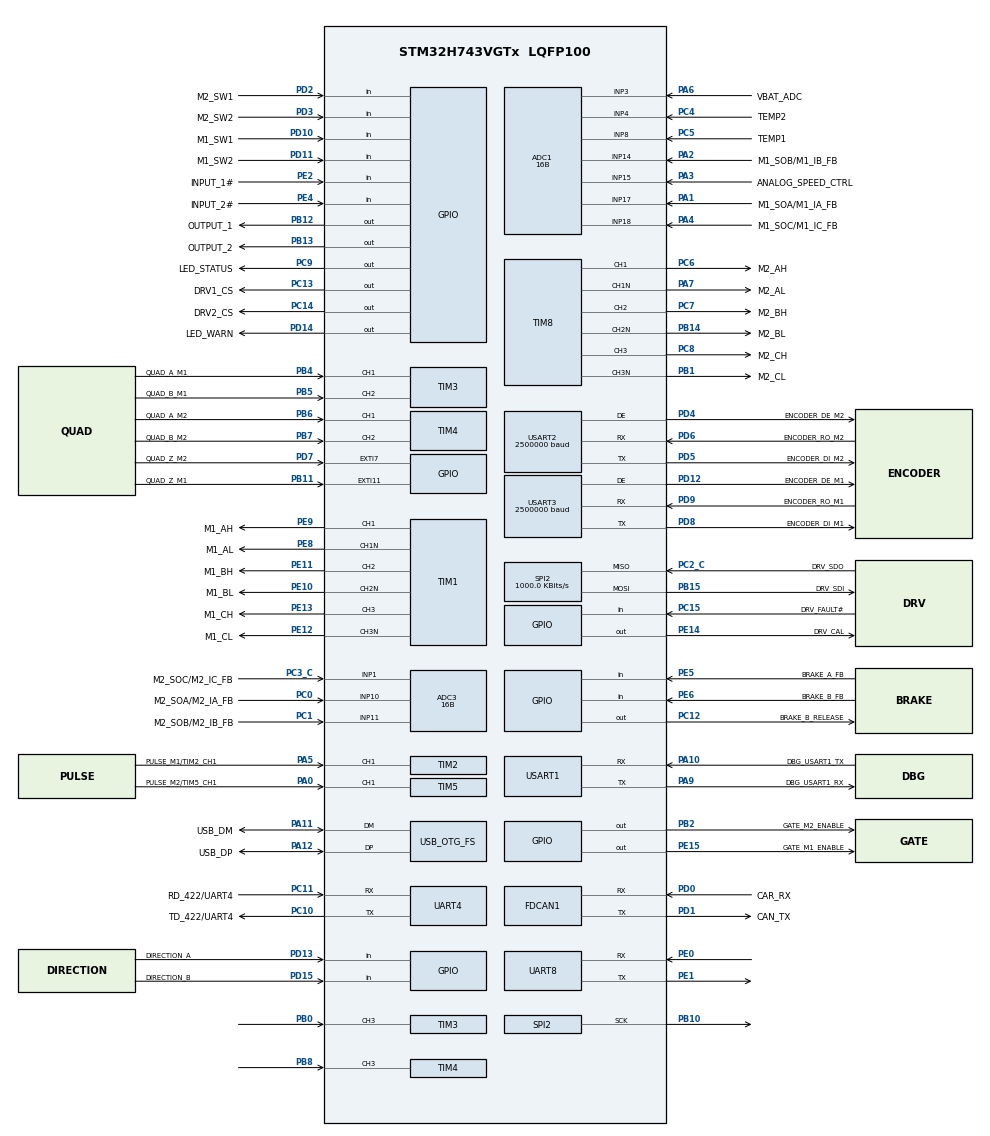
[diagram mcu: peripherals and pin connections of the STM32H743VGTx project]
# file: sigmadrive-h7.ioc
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ADC1.Channel-1\#ChannelRegularConversion=ADC_CHANNEL_17
ADC1.Channel-2\#ChannelRegularConversion=ADC_CHANNEL_14
ADC1.Channel-3\#ChannelRegularConversion=ADC_CHANNEL_18
ADC1.Channel-4\#ChannelRegularConversion=ADC_CHANNEL_3
ADC1.Channel-5\#ChannelRegularConversion=ADC_CHANNEL_4
ADC1.Channel-6\#ChannelRegularConversion=ADC_CHANNEL_8
ADC1.Channel-7\#ChannelRegularConversion=ADC_CHANNEL_15
ADC1.ClockPrescaler=ADC_CLOCK_ASYNC_DIV2
ADC1.ClockPrescalerADC3=ADC_CLOCK_ASYNC_DIV2
ADC1.ConversionDataManagement=ADC_CONVERSIONDATA_DMA_CIRCULAR
ADC1.EOCSelection=ADC_EOC_SEQ_CONV
ADC1.EnableInjectedConversion=ENABLE
ADC1.ExternalTrigConv=ADC_EXTERNALTRIG_T1_TRGO2
ADC1.ExternalTrigConvEdge=ADC_EXTERNALTRIGCONVEDGE_RISINGFALLING
ADC1.ExternalTrigInjecConv=ADC_EXTERNALTRIGINJEC_T1_TRGO2
ADC1.ExternalTrigInjecConvEdge=ADC_EXTERNALTRIGINJECCONV_EDGE_RISINGFALLING
ADC1.InjNumberOfConversion=3
ADC1.InjectedChannel-10\#ChannelInjectedConversion=ADC_CHANNEL_18
ADC1.InjectedChannel-8\#ChannelInjectedConversion=ADC_CHANNEL_17
ADC1.InjectedChannel-9\#ChannelInjectedConversion=ADC_CHANNEL_14
ADC1.InjectedOffsetNumber-10\#ChannelInjectedConversion=ADC_OFFSET_NONE
ADC1.InjectedOffsetNumber-8\#ChannelInjectedConversion=ADC_OFFSET_NONE
ADC1.InjectedOffsetNumber-9\#ChannelInjectedConversion=ADC_OFFSET_NONE
ADC1.InjectedOffsetSaturation-10\#ChannelInjectedConversion=DISABLE
ADC1.InjectedOffsetSaturation-8\#ChannelInjectedConversion=DISABLE
ADC1.InjectedOffsetSaturation-9\#ChannelInjectedConversion=DISABLE
ADC1.InjectedRank-10\#ChannelInjectedConversion=3
ADC1.InjectedRank-8\#ChannelInjectedConversion=1
ADC1.InjectedRank-9\#ChannelInjectedConversion=2
ADC1.InjectedSamplingTime-10\#ChannelInjectedConversion=ADC_SAMPLETIME_1CYCLE_5
ADC1.InjectedSamplingTime-8\#ChannelInjectedConversion=ADC_SAMPLETIME_1CYCLE_5
ADC1.InjectedSamplingTime-9\#ChannelInjectedConversion=ADC_SAMPLETIME_1CYCLE_5
ADC1.NbrOfConversion=7
ADC1.NbrOfConversionFlag=1
ADC1.OffsetNumber-2\#ChannelRegularConversion=ADC_OFFSET_NONE
ADC1.OffsetNumber-3\#ChannelRegularConversion=ADC_OFFSET_NONE
ADC1.OffsetNumber-4\#ChannelRegularConversion=ADC_OFFSET_NONE
ADC1.OffsetNumber-5\#ChannelRegularConversion=ADC_OFFSET_NONE
ADC1.OffsetNumber-6\#ChannelRegularConversion=ADC_OFFSET_NONE
ADC1.OffsetNumber-7\#ChannelRegularConversion=ADC_OFFSET_NONE
ADC1.Rank-2\#ChannelRegularConversion=2
ADC1.Rank-3\#ChannelRegularConversion=3
ADC1.Rank-4\#ChannelRegularConversion=4
ADC1.Rank-5\#ChannelRegularConversion=5
ADC1.Rank-6\#ChannelRegularConversion=6
ADC1.Rank-7\#ChannelRegularConversion=7
ADC1.Resolution=ADC_RESOLUTION_16B
ADC1.SamplingTime-1\#ChannelRegularConversion=ADC_SAMPLETIME_1CYCLE_5
ADC1.SamplingTime-2\#ChannelRegularConversion=ADC_SAMPLETIME_1CYCLE_5
ADC1.SamplingTime-3\#ChannelRegularConversion=ADC_SAMPLETIME_1CYCLE_5
ADC1.SamplingTime-4\#ChannelRegularConversion=ADC_SAMPLETIME_1CYCLE_5
ADC1.SamplingTime-5\#ChannelRegularConversion=ADC_SAMPLETIME_1CYCLE_5
ADC1.SamplingTime-6\#ChannelRegularConversion=ADC_SAMPLETIME_1CYCLE_5
ADC1.SamplingTime-7\#ChannelRegularConversion=ADC_SAMPLETIME_1CYCLE_5
ADC1.master=1
ADC3.Channel-0\#ChannelRegularConversion=ADC_CHANNEL_10
ADC3.Channel-1\#ChannelRegularConversion=ADC_CHANNEL_11
ADC3.Channel-2\#ChannelRegularConversion=ADC_CHANNEL_1
ADC3.ClockPrescaler=ADC_CLOCK_ASYNC_DIV2
ADC3.ClockPrescalerADC3=ADC_CLOCK_ASYNC_DIV2
ADC3.ConversionDataManagement=ADC_CONVERSIONDATA_DMA_CIRCULAR
ADC3.EnableInjectedConversion=ENABLE
ADC3.ExternalTrigConv=ADC_EXTERNALTRIG_T8_TRGO2
ADC3.ExternalTrigInjecConv=ADC_EXTERNALTRIGINJEC_T8_TRGO2
ADC3.ExternalTrigInjecConvEdge=ADC_EXTERNALTRIGINJECCONV_EDGE_RISINGFALLING
ADC3.InjNumberOfConversion=3
ADC3.InjectedChannel-3\#ChannelInjectedConversion=ADC_CHANNEL_10
ADC3.InjectedChannel-4\#ChannelInjectedConversion=ADC_CHANNEL_11
ADC3.InjectedChannel-5\#ChannelInjectedConversion=ADC_CHANNEL_1
ADC3.InjectedOffsetNumber-3\#ChannelInjectedConversion=ADC_OFFSET_NONE
ADC3.InjectedOffsetNumber-4\#ChannelInjectedConversion=ADC_OFFSET_NONE
ADC3.InjectedOffsetNumber-5\#ChannelInjectedConversion=ADC_OFFSET_NONE
ADC3.InjectedOffsetSaturation-3\#ChannelInjectedConversion=DISABLE
ADC3.InjectedOffsetSaturation-4\#ChannelInjectedConversion=DISABLE
ADC3.InjectedOffsetSaturation-5\#ChannelInjectedConversion=DISABLE
ADC3.InjectedOffsetSignedSaturation-3\#ChannelInjectedConversion=DISABLE
ADC3.InjectedOffsetSignedSaturation-4\#ChannelInjectedConversion=DISABLE
ADC3.InjectedOffsetSignedSaturation-5\#ChannelInjectedConversion=DISABLE
ADC3.InjectedRank-3\#ChannelInjectedConversion=1
ADC3.InjectedRank-4\#ChannelInjectedConversion=2
ADC3.InjectedRank-5\#ChannelInjectedConversion=3
ADC3.InjectedSamplingTime-3\#ChannelInjectedConversion=ADC_SAMPLETIME_1CYCLE_5
ADC3.InjectedSamplingTime-4\#ChannelInjectedConversion=ADC_SAMPLETIME_1CYCLE_5
ADC3.InjectedSamplingTime-5\#ChannelInjectedConversion=ADC_SAMPLETIME_1CYCLE_5
ADC3.NbrOfConversion=3
ADC3.NbrOfConversionFlag=1
ADC3.OffsetNumber-0\#ChannelRegularConversion=ADC_OFFSET_NONE
ADC3.OffsetNumber-1\#ChannelRegularConversion=ADC_OFFSET_NONE
ADC3.OffsetNumber-2\#ChannelRegularConversion=ADC_OFFSET_NONE
ADC3.OffsetSignedSaturation-0\#ChannelRegularConversion=DISABLE
ADC3.OffsetSignedSaturation-1\#ChannelRegularConversion=DISABLE
ADC3.OffsetSignedSaturation-2\#ChannelRegularConversion=DISABLE
ADC3.Rank-0\#ChannelRegularConversion=1
ADC3.Rank-1\#ChannelRegularConversion=2
ADC3.Rank-2\#ChannelRegularConversion=3
ADC3.Resolution=ADC_RESOLUTION_16B
ADC3.SamplingTime-0\#ChannelRegularConversion=ADC_SAMPLETIME_1CYCLE_5
ADC3.SamplingTime-1\#ChannelRegularConversion=ADC_SAMPLETIME_1CYCLE_5
ADC3.SamplingTime-2\#ChannelRegularConversion=ADC_SAMPLETIME_1CYCLE_5
ADC3.injectedQueueMode=DISABLE
CORTEX_M7.CPU_DCache=Disabled
CORTEX_M7.CPU_ICache=Disabled
CORTEX_M7.MPU_Control=__NULL
CORTEX_M7.default_mode_Activation=0
Dma.ADC1.8.Direction=DMA_PERIPH_TO_MEMORY
Dma.ADC1.8.EventEnable=DISABLE
Dma.ADC1.8.FIFOMode=DMA_FIFOMODE_ENABLE
Dma.ADC1.8.FIFOThreshold=DMA_FIFO_THRESHOLD_FULL
Dma.ADC1.8.Instance=DMA2_Stream0
Dma.ADC1.8.MemBurst=DMA_MBURST_SINGLE
Dma.ADC1.8.MemDataAlignment=DMA_MDATAALIGN_WORD
Dma.ADC1.8.MemInc=DMA_MINC_ENABLE
Dma.ADC1.8.Mode=DMA_CIRCULAR
Dma.ADC1.8.PeriphBurst=DMA_PBURST_SINGLE
Dma.ADC1.8.PeriphDataAlignment=DMA_PDATAALIGN_WORD
Dma.ADC1.8.PeriphInc=DMA_PINC_DISABLE
Dma.ADC1.8.Polarity=HAL_DMAMUX_REQ_GEN_RISING
Dma.ADC1.8.Priority=DMA_PRIORITY_LOW
Dma.ADC1.8.RequestNumber=1
Dma.ADC1.8.SignalID=NONE
Dma.ADC1.8.SyncEnable=DISABLE
Dma.ADC1.8.SyncPolarity=HAL_DMAMUX_SYNC_NO_EVENT
Dma.ADC1.8.SyncRequestNumber=1
Dma.ADC1.8.SyncSignalID=NONE
Dma.ADC3.9.Direction=DMA_PERIPH_TO_MEMORY
Dma.ADC3.9.EventEnable=DISABLE
Dma.ADC3.9.FIFOMode=DMA_FIFOMODE_ENABLE
Dma.ADC3.9.FIFOThreshold=DMA_FIFO_THRESHOLD_FULL
Dma.ADC3.9.Instance=DMA2_Stream2
Dma.ADC3.9.MemBurst=DMA_MBURST_SINGLE
Dma.ADC3.9.MemDataAlignment=DMA_MDATAALIGN_WORD
Dma.ADC3.9.MemInc=DMA_MINC_ENABLE
Dma.ADC3.9.Mode=DMA_CIRCULAR
Dma.ADC3.9.PeriphBurst=DMA_PBURST_SINGLE
Dma.ADC3.9.PeriphDataAlignment=DMA_PDATAALIGN_WORD
Dma.ADC3.9.PeriphInc=DMA_PINC_DISABLE
Dma.ADC3.9.Polarity=HAL_DMAMUX_REQ_GEN_RISING
Dma.ADC3.9.Priority=DMA_PRIORITY_LOW
Dma.ADC3.9.RequestNumber=1
Dma.ADC3.9.SignalID=NONE
Dma.ADC3.9.SyncEnable=DISABLE
Dma.ADC3.9.SyncPolarity=HAL_DMAMUX_SYNC_NO_EVENT
Dma.ADC3.9.SyncRequestNumber=1
Dma.ADC3.9.SyncSignalID=NONE
Dma.Request0=UART8_TX
Dma.Request1=UART8_RX
Dma.Request2=USART1_TX
Dma.Request3=USART1_RX
Dma.Request4=USART2_RX
Dma.Request5=USART3_RX
Dma.Request6=UART4_TX
Dma.Request7=UART4_RX
Dma.Request8=ADC1
Dma.Request9=ADC3
Dma.UART4_RX.7.Direction=DMA_PERIPH_TO_MEMORY
Dma.UART4_RX.7.EventEnable=DISABLE
Dma.UART4_RX.7.FIFOMode=DMA_FIFOMODE_DISABLE
Dma.UART4_RX.7.Instance=DMA1_Stream2
Dma.UART4_RX.7.MemDataAlignment=DMA_MDATAALIGN_BYTE
Dma.UART4_RX.7.MemInc=DMA_MINC_ENABLE
Dma.UART4_RX.7.Mode=DMA_CIRCULAR
Dma.UART4_RX.7.PeriphDataAlignment=DMA_PDATAALIGN_BYTE
Dma.UART4_RX.7.PeriphInc=DMA_PINC_DISABLE
Dma.UART4_RX.7.Polarity=HAL_DMAMUX_REQ_GEN_RISING
Dma.UART4_RX.7.Priority=DMA_PRIORITY_LOW
Dma.UART4_RX.7.RequestNumber=1
Dma.UART4_RX.7.SignalID=NONE
Dma.UART4_RX.7.SyncEnable=DISABLE
Dma.UART4_RX.7.SyncPolarity=HAL_DMAMUX_SYNC_NO_EVENT
Dma.UART4_RX.7.SyncRequestNumber=1
Dma.UART4_RX.7.SyncSignalID=NONE
Dma.UART4_TX.6.Direction=DMA_MEMORY_TO_PERIPH
Dma.UART4_TX.6.EventEnable=DISABLE
Dma.UART4_TX.6.FIFOMode=DMA_FIFOMODE_DISABLE
Dma.UART4_TX.6.Instance=DMA1_Stream4
Dma.UART4_TX.6.MemDataAlignment=DMA_MDATAALIGN_BYTE
Dma.UART4_TX.6.MemInc=DMA_MINC_ENABLE
Dma.UART4_TX.6.Mode=DMA_NORMAL
Dma.UART4_TX.6.PeriphDataAlignment=DMA_PDATAALIGN_BYTE
Dma.UART4_TX.6.PeriphInc=DMA_PINC_DISABLE
Dma.UART4_TX.6.Polarity=HAL_DMAMUX_REQ_GEN_RISING
Dma.UART4_TX.6.Priority=DMA_PRIORITY_LOW
Dma.UART4_TX.6.RequestNumber=1
Dma.UART4_TX.6.SignalID=NONE
Dma.UART4_TX.6.SyncEnable=DISABLE
Dma.UART4_TX.6.SyncPolarity=HAL_DMAMUX_SYNC_NO_EVENT
Dma.UART4_TX.6.SyncRequestNumber=1
Dma.UART4_TX.6.SyncSignalID=NONE
Dma.UART8_RX.1.Direction=DMA_PERIPH_TO_MEMORY
Dma.UART8_RX.1.EventEnable=DISABLE
Dma.UART8_RX.1.FIFOMode=DMA_FIFOMODE_DISABLE
Dma.UART8_RX.1.Instance=DMA1_Stream6
Dma.UART8_RX.1.MemDataAlignment=DMA_MDATAALIGN_BYTE
Dma.UART8_RX.1.MemInc=DMA_MINC_ENABLE
Dma.UART8_RX.1.Mode=DMA_CIRCULAR
Dma.UART8_RX.1.PeriphDataAlignment=DMA_PDATAALIGN_BYTE
Dma.UART8_RX.1.PeriphInc=DMA_PINC_DISABLE
Dma.UART8_RX.1.Polarity=HAL_DMAMUX_REQ_GEN_RISING
Dma.UART8_RX.1.Priority=DMA_PRIORITY_LOW
Dma.UART8_RX.1.RequestNumber=1
Dma.UART8_RX.1.SignalID=NONE
Dma.UART8_RX.1.SyncEnable=DISABLE
Dma.UART8_RX.1.SyncPolarity=HAL_DMAMUX_SYNC_NO_EVENT
Dma.UART8_RX.1.SyncRequestNumber=1
Dma.UART8_RX.1.SyncSignalID=NONE
Dma.UART8_TX.0.Direction=DMA_MEMORY_TO_PERIPH
Dma.UART8_TX.0.EventEnable=DISABLE
Dma.UART8_TX.0.FIFOMode=DMA_FIFOMODE_DISABLE
Dma.UART8_TX.0.Instance=DMA1_Stream0
Dma.UART8_TX.0.MemDataAlignment=DMA_MDATAALIGN_BYTE
Dma.UART8_TX.0.MemInc=DMA_MINC_ENABLE
Dma.UART8_TX.0.Mode=DMA_NORMAL
Dma.UART8_TX.0.PeriphDataAlignment=DMA_PDATAALIGN_BYTE
Dma.UART8_TX.0.PeriphInc=DMA_PINC_DISABLE
Dma.UART8_TX.0.Polarity=HAL_DMAMUX_REQ_GEN_RISING
Dma.UART8_TX.0.Priority=DMA_PRIORITY_LOW
Dma.UART8_TX.0.RequestNumber=1
Dma.UART8_TX.0.SignalID=NONE
Dma.UART8_TX.0.SyncEnable=DISABLE
Dma.UART8_TX.0.SyncPolarity=HAL_DMAMUX_SYNC_NO_EVENT
Dma.UART8_TX.0.SyncRequestNumber=1
Dma.UART8_TX.0.SyncSignalID=NONE
Dma.USART1_RX.3.Direction=DMA_PERIPH_TO_MEMORY
Dma.USART1_RX.3.EventEnable=DISABLE
Dma.USART1_RX.3.FIFOMode=DMA_FIFOMODE_DISABLE
Dma.USART1_RX.3.Instance=DMA2_Stream5
Dma.USART1_RX.3.MemDataAlignment=DMA_MDATAALIGN_BYTE
Dma.USART1_RX.3.MemInc=DMA_MINC_ENABLE
Dma.USART1_RX.3.Mode=DMA_CIRCULAR
Dma.USART1_RX.3.PeriphDataAlignment=DMA_PDATAALIGN_BYTE
Dma.USART1_RX.3.PeriphInc=DMA_PINC_DISABLE
Dma.USART1_RX.3.Polarity=HAL_DMAMUX_REQ_GEN_RISING
Dma.USART1_RX.3.Priority=DMA_PRIORITY_LOW
Dma.USART1_RX.3.RequestNumber=1
Dma.USART1_RX.3.SignalID=NONE
Dma.USART1_RX.3.SyncEnable=DISABLE
Dma.USART1_RX.3.SyncPolarity=HAL_DMAMUX_SYNC_NO_EVENT
Dma.USART1_RX.3.SyncRequestNumber=1
Dma.USART1_RX.3.SyncSignalID=NONE
Dma.USART1_TX.2.Direction=DMA_MEMORY_TO_PERIPH
Dma.USART1_TX.2.EventEnable=DISABLE
Dma.USART1_TX.2.FIFOMode=DMA_FIFOMODE_DISABLE
Dma.USART1_TX.2.Instance=DMA2_Stream7
Dma.USART1_TX.2.MemDataAlignment=DMA_MDATAALIGN_BYTE
Dma.USART1_TX.2.MemInc=DMA_MINC_ENABLE
Dma.USART1_TX.2.Mode=DMA_NORMAL
Dma.USART1_TX.2.PeriphDataAlignment=DMA_PDATAALIGN_BYTE
Dma.USART1_TX.2.PeriphInc=DMA_PINC_DISABLE
Dma.USART1_TX.2.Polarity=HAL_DMAMUX_REQ_GEN_RISING
Dma.USART1_TX.2.Priority=DMA_PRIORITY_LOW
Dma.USART1_TX.2.RequestNumber=1
Dma.USART1_TX.2.SignalID=NONE
Dma.USART1_TX.2.SyncEnable=DISABLE
Dma.USART1_TX.2.SyncPolarity=HAL_DMAMUX_SYNC_NO_EVENT
Dma.USART1_TX.2.SyncRequestNumber=1
Dma.USART1_TX.2.SyncSignalID=NONE
Dma.USART2_RX.4.Direction=DMA_PERIPH_TO_MEMORY
Dma.USART2_RX.4.EventEnable=DISABLE
Dma.USART2_RX.4.FIFOMode=DMA_FIFOMODE_DISABLE
Dma.USART2_RX.4.Instance=DMA1_Stream5
Dma.USART2_RX.4.MemDataAlignment=DMA_MDATAALIGN_BYTE
Dma.USART2_RX.4.MemInc=DMA_MINC_ENABLE
Dma.USART2_RX.4.Mode=DMA_NORMAL
Dma.USART2_RX.4.PeriphDataAlignment=DMA_PDATAALIGN_BYTE
Dma.USART2_RX.4.PeriphInc=DMA_PINC_DISABLE
Dma.USART2_RX.4.Polarity=HAL_DMAMUX_REQ_GEN_RISING
Dma.USART2_RX.4.Priority=DMA_PRIORITY_VERY_HIGH
Dma.USART2_RX.4.RequestNumber=1
Dma.USART2_RX.4.SignalID=NONE
Dma.USART2_RX.4.SyncEnable=DISABLE
Dma.USART2_RX.4.SyncPolarity=HAL_DMAMUX_SYNC_NO_EVENT
Dma.USART2_RX.4.SyncRequestNumber=1
Dma.USART2_RX.4.SyncSignalID=NONE
Dma.USART3_RX.5.Direction=DMA_PERIPH_TO_MEMORY
Dma.USART3_RX.5.EventEnable=DISABLE
Dma.USART3_RX.5.FIFOMode=DMA_FIFOMODE_DISABLE
Dma.USART3_RX.5.Instance=DMA1_Stream1
Dma.USART3_RX.5.MemDataAlignment=DMA_MDATAALIGN_BYTE
Dma.USART3_RX.5.MemInc=DMA_MINC_ENABLE
Dma.USART3_RX.5.Mode=DMA_NORMAL
Dma.USART3_RX.5.PeriphDataAlignment=DMA_PDATAALIGN_BYTE
Dma.USART3_RX.5.PeriphInc=DMA_PINC_DISABLE
Dma.USART3_RX.5.Polarity=HAL_DMAMUX_REQ_GEN_RISING
Dma.USART3_RX.5.Priority=DMA_PRIORITY_VERY_HIGH
Dma.USART3_RX.5.RequestNumber=1
Dma.USART3_RX.5.SignalID=NONE
Dma.USART3_RX.5.SyncEnable=DISABLE
Dma.USART3_RX.5.SyncPolarity=HAL_DMAMUX_SYNC_NO_EVENT
Dma.USART3_RX.5.SyncRequestNumber=1
Dma.USART3_RX.5.SyncSignalID=NONE
FDCAN1.CalculateBaudRateNominal=150000
FDCAN1.CalculateTimeBitNominal=6666
FDCAN1.CalculateTimeQuantumNominal=1333.3333333333333
FREERTOS.HEAP_NUMBER=3
FREERTOS.Tasks01=defaultTask,24,2048,StartDefaultTask,Default,NULL,Dynamic,NULL,NULL
FREERTOS.configTOTAL_HEAP_SIZE=353600
Mcu.Family=STM32H7
Mcu.Name=STM32H743VGTx
Mcu.Package=LQFP100
Mcu.UserConstants=TIM1_PERIOD_CLOCKS,6000;TIM1_RCR,0;TIMER_CORE_CLOCK,240000000
NVIC.ADC3_IRQn=true\:5\:0\:false\:false\:true\:true\:true\:true\:true
NVIC.ADC_IRQn=true\:5\:0\:false\:false\:true\:true\:true\:true\:true
NVIC.DMA1_Stream0_IRQn=true\:5\:0\:false\:false\:true\:true\:false\:true\:true
NVIC.DMA1_Stream1_IRQn=true\:5\:0\:false\:false\:true\:true\:false\:true\:true
NVIC.DMA1_Stream2_IRQn=true\:5\:0\:false\:false\:true\:true\:false\:true\:true
NVIC.DMA1_Stream4_IRQn=true\:5\:0\:false\:false\:true\:false\:false\:true\:true
NVIC.DMA1_Stream5_IRQn=true\:5\:0\:false\:false\:true\:false\:false\:true\:true
NVIC.DMA1_Stream6_IRQn=true\:5\:0\:false\:false\:true\:true\:false\:true\:true
NVIC.DMA2_Stream0_IRQn=true\:5\:0\:false\:false\:true\:true\:false\:true\:true
NVIC.DMA2_Stream2_IRQn=true\:5\:0\:false\:false\:true\:false\:false\:true\:true
NVIC.DMA2_Stream5_IRQn=true\:5\:0\:false\:false\:true\:false\:false\:true\:true
NVIC.DMA2_Stream7_IRQn=true\:5\:0\:false\:false\:true\:false\:false\:true\:true
NVIC.OTG_FS_IRQn=true\:5\:0\:false\:false\:true\:true\:false\:true\:true
NVIC.PriorityGroup=NVIC_PRIORITYGROUP_4
NVIC.TIM1_UP_IRQn=true\:5\:0\:false\:false\:true\:true\:true\:true\:true
NVIC.TIM7_IRQn=true\:15\:0\:false\:false\:true\:false\:false\:true\:true
NVIC.TimeBase=TIM7_IRQn
NVIC.TimeBaseIP=TIM7
NVIC.UART4_IRQn=true\:5\:0\:false\:false\:true\:true\:true\:true\:true
NVIC.UART8_IRQn=true\:5\:0\:false\:false\:true\:true\:true\:true\:true
NVIC.USART1_IRQn=true\:5\:0\:false\:false\:true\:true\:true\:true\:true
NVIC.USART2_IRQn=true\:5\:0\:false\:false\:true\:true\:true\:true\:true
NVIC.USART3_IRQn=true\:5\:0\:false\:false\:true\:true\:true\:true\:true
PA0.GPIO_Label=PULSE_M2/TIM5_CH1
PA0.Signal=S_TIM5_CH1
PA1.GPIO_Label=M1_SOA/M1_IA_FB
PA1.GPIO_Mode=GPIO_MODE_ANALOG
PA1.GPIO_PuPd=GPIO_NOPULL
PA1.Mode=IN17-Single-Ended
PA1.Signal=ADC1_INP17
PA10.GPIO_Label=DBG_USART1_TX
PA10.GPIO_Speed=GPIO_SPEED_FREQ_VERY_HIGH
PA10.Mode=Asynchronous
PA10.Signal=USART1_RX
PA11.GPIO_Label=USB_DM
PA11.Mode=Device_Only
PA11.Signal=USB_OTG_FS_DM
PA12.GPIO_Label=USB_DP
PA12.Mode=Device_Only
PA12.Signal=USB_OTG_FS_DP
PA13\ (JTMS/SWDIO).Signal=DEBUG_JTMS-SWDIO
PA14\ (JTCK/SWCLK).Signal=DEBUG_JTCK-SWCLK
PA2.GPIO_Label=M1_SOB/M1_IB_FB
PA2.GPIO_Mode=GPIO_MODE_ANALOG
PA2.GPIO_PuPd=GPIO_NOPULL
PA2.Signal=ADCx_INP14
PA3.GPIO_Label=ANALOG_SPEED_CTRL
PA3.GPIO_Mode=GPIO_MODE_ANALOG
PA3.GPIO_PuPd=GPIO_NOPULL
PA3.Signal=ADCx_INP15
PA4.GPIO_Label=M1_SOC/M1_IC_FB
PA4.GPIO_Mode=GPIO_MODE_ANALOG
PA4.GPIO_PuPd=GPIO_NOPULL
PA4.Signal=ADCx_INP18
PA5.GPIO_Label=PULSE_M1/TIM2_CH1
PA5.Signal=S_TIM2_CH1_ETR
PA6.GPIO_Label=VBAT_ADC
PA6.GPIO_Mode=GPIO_MODE_ANALOG
PA6.GPIO_PuPd=GPIO_NOPULL
PA6.Signal=ADCx_INP3
PA7.GPIO_Label=M2_AL
PA7.Mode=PWM Generation1 CH1 CH1N
PA7.Signal=TIM8_CH1N
PA9.GPIO_Label=DBG_USART1_RX
PA9.GPIO_Speed=GPIO_SPEED_FREQ_VERY_HIGH
PA9.Mode=Asynchronous
PA9.Signal=USART1_TX
PB0.Signal=S_TIM3_CH3
PB1.GPIO_Label=M2_CL
PB1.Mode=PWM Generation3 CH3 CH3N
PB1.Signal=TIM8_CH3N
PB10.Mode=Full_Duplex_Master
PB10.Signal=SPI2_SCK
PB11.GPIO_Label=QUAD_Z_M1
PB11.Signal=GPXTI11
PB12.GPIO_Label=OUTPUT_1
PB12.Signal=GPIO_Output
PB13.GPIO_Label=OUTPUT_2
PB13.Signal=GPIO_Output
PB14.GPIO_Label=M2_BL
PB14.Mode=PWM Generation2 CH2 CH2N
PB14.Signal=TIM8_CH2N
PB15.GPIO_Label=DRV_SDI
PB15.Mode=Full_Duplex_Master
PB15.Signal=SPI2_MOSI
PB2.GPIO_Label=GATE_M2_ENABLE
PB2.Signal=GPIO_Output
PB3\ (JTDO/TRACESWO).Signal=DEBUG_JTDO-SWO
PB4\ (NJTRST).GPIO_Label=QUAD_A_M1
PB4\ (NJTRST).Signal=S_TIM3_CH1
PB5.GPIO_Label=QUAD_B_M1
PB5.Signal=S_TIM3_CH2
PB6.GPIO_Label=QUAD_A_M2
PB6.Signal=S_TIM4_CH1
PB7.GPIO_Label=QUAD_B_M2
PB7.Signal=S_TIM4_CH2
PB8.Signal=S_TIM4_CH3
PC0.GPIO_Label=M2_SOA/M2_IA_FB
PC0.Signal=ADCx_INP10
PC1.GPIO_Label=M2_SOB/M2_IB_FB
PC1.Signal=ADCx_INP11
PC10.GPIO_Label=TD_422/UART4
PC10.Mode=Asynchronous
PC10.Signal=UART4_TX
PC11.GPIO_Label=RD_422/UART4
PC11.Mode=Asynchronous
PC11.Signal=UART4_RX
PC12.GPIO_Label=BRAKE_B_RELEASE
PC12.Signal=GPIO_Output
PC13.GPIO_Label=DRV1_CS
PC13.Signal=GPIO_Output
PC14-OSC32_IN\ (OSC32_IN).GPIO_Label=DRV2_CS
PC14-OSC32_IN\ (OSC32_IN).Signal=GPIO_Output
PC15-OSC32_OUT\ (OSC32_OUT).GPIO_Label=DRV_FAULT\#
PC15-OSC32_OUT\ (OSC32_OUT).Signal=GPIO_Input
PC2_C.GPIO_Label=DRV_SDO
PC2_C.Mode=Full_Duplex_Master
PC2_C.Signal=SPI2_MISO
PC3_C.GPIO_Label=M2_SOC/M2_IC_FB
PC3_C.Mode=IN1-Single-Ended
PC3_C.Signal=ADC3_INP1
PC4.GPIO_Label=TEMP2
PC4.GPIO_Mode=GPIO_MODE_ANALOG
PC4.GPIO_PuPd=GPIO_NOPULL
PC4.Signal=ADCx_INP4
PC5.GPIO_Label=TEMP1
PC5.GPIO_Mode=GPIO_MODE_ANALOG
PC5.GPIO_PuPd=GPIO_NOPULL
PC5.Signal=ADCx_INP8
PC6.GPIO_Label=M2_AH
PC6.Signal=S_TIM8_CH1
PC7.GPIO_Label=M2_BH
PC7.Signal=S_TIM8_CH2
PC8.GPIO_Label=M2_CH
PC8.Signal=S_TIM8_CH3
PC9.GPIO_Label=LED_STATUS
PC9.Signal=GPIO_Output
PD0.GPIO_Label=CAR_RX
PD0.Mode=FDCAN_Activate
PD0.Signal=FDCAN1_RX
PD1.GPIO_Label=CAN_TX
PD1.Mode=FDCAN_Activate
PD1.Signal=FDCAN1_TX
PD10.GPIO_Label=M1_SW1
PD10.Signal=GPIO_Input
PD11.GPIO_Label=M1_SW2
PD11.Signal=GPIO_Input
PD12.GPIO_Label=ENCODER_DE_M1
PD12.Mode=Hardware Flow Control (RS485)
PD12.Signal=USART3_DE
PD13.GPIO_Label=DIRECTION_A
PD13.Signal=GPIO_Input
PD14.GPIO_Label=LED_WARN
PD14.Signal=GPIO_Output
PD15.GPIO_Label=DIRECTION_B
PD15.Signal=GPIO_Input
PD2.GPIO_Label=M2_SW1
PD2.Signal=GPIO_Input
PD3.GPIO_Label=M2_SW2
PD3.Signal=GPIO_Input
PD4.GPIO_Label=ENCODER_DE_M2
PD4.Mode=Hardware Flow Control (RS485)
PD4.Signal=USART2_DE
PD5.GPIO_Label=ENCODER_DI_M2
PD5.Mode=Asynchronous
PD5.Signal=USART2_TX
PD6.GPIO_Label=ENCODER_RO_M2
PD6.Mode=Asynchronous
PD6.Signal=USART2_RX
PD7.GPIO_Label=QUAD_Z_M2
PD7.Signal=GPXTI7
PD8.GPIO_Label=ENCODER_DI_M1
PD8.Mode=Asynchronous
PD8.Signal=USART3_TX
PD9.GPIO_Label=ENCODER_RO_M1
PD9.Mode=Asynchronous
PD9.Signal=USART3_RX
PE0.GPIO_Speed=GPIO_SPEED_FREQ_VERY_HIGH
PE0.Mode=Asynchronous
PE0.Signal=UART8_RX
PE1.GPIO_Speed=GPIO_SPEED_FREQ_VERY_HIGH
PE1.Mode=Asynchronous
PE1.Signal=UART8_TX
PE10.GPIO_Label=M1_BL
PE10.Mode=PWM Generation2 CH2 CH2N
PE10.Signal=TIM1_CH2N
PE11.GPIO_Label=M1_BH
PE11.Signal=S_TIM1_CH2
PE12.GPIO_Label=M1_CL
PE12.Mode=PWM Generation3 CH3 CH3N
PE12.Signal=TIM1_CH3N
PE13.GPIO_Label=M1_CH
PE13.Signal=S_TIM1_CH3
PE14.GPIO_Label=DRV_CAL
PE14.Signal=GPIO_Output
PE15.GPIO_Label=GATE_M1_ENABLE
PE15.Signal=GPIO_Output
PE2.GPIO_Label=INPUT_1\#
PE2.Signal=GPIO_Input
PE4.GPIO_Label=INPUT_2\#
PE4.Signal=GPIO_Input
PE5.GPIO_Label=BRAKE_A_FB
PE5.Signal=GPIO_Input
PE6.GPIO_Label=BRAKE_B_FB
PE6.Signal=GPIO_Input
PE8.GPIO_Label=M1_AL
PE8.Mode=PWM Generation1 CH1 CH1N
PE8.Signal=TIM1_CH1N
PE9.GPIO_Label=M1_AH
PE9.Signal=S_TIM1_CH1
PH0-OSC_IN\ (PH0).Mode=HSE-External-Oscillator
PH0-OSC_IN\ (PH0).Signal=RCC_OSC_IN
PH1-OSC_OUT\ (PH1).Mode=HSE-External-Oscillator
PH1-OSC_OUT\ (PH1).Signal=RCC_OSC_OUT
ProjectManager.HeapSize=0x200
ProjectManager.StackSize=0x400
ProjectManager.TargetToolchain=Makefile
RCC.ADCFreq_Value=37500000
RCC.APB1Freq_Value=120000000
RCC.APB2Freq_Value=120000000
RCC.APB3Freq_Value=120000000
RCC.APB4Freq_Value=120000000
RCC.CortexFreq_Value=480000000
RCC.D1PPRE=RCC_APB3_DIV2
RCC.D2PPRE1=RCC_APB1_DIV2
RCC.D2PPRE2=RCC_APB2_DIV2
RCC.D3PPRE=RCC_APB4_DIV2
RCC.DIVM1=3
RCC.DIVM2=1
RCC.DIVM3=1
RCC.DIVN1=240
RCC.DIVN2=12
RCC.DIVN3=16
RCC.DIVP2=4
RCC.DIVQ1=7
RCC.DIVQ2=3
RCC.DIVQ3=4
RCC.FDCANCLockSelection=RCC_FDCANCLKSOURCE_HSE
RCC.HCLKFreq_Value=240000000
RCC.HPRE=RCC_HCLK_DIV2
RCC.HSE_VALUE=12000000
RCC.PLL1_VCI_Range-AdvancedSettings=RCC_PLL1VCIRANGE_3
RCC.PLL1_VCO_SEL-AdvancedSettings=RCC_PLL1VCOMEDIUM
RCC.PLL2FRACN=4096
RCC.PLL3FRACN=0
RCC.PLLFRACN=0
RCC.PLLSourceVirtual=RCC_PLLSOURCE_HSE
RCC.ProductRev=revV
RCC.SPI123CLockSelection=RCC_SPI123CLKSOURCE_CLKP
RCC.SYSCLKFreq_VALUE=480000000
RCC.SYSCLKSource=RCC_SYSCLKSOURCE_PLLCLK
RCC.USART16CLockSelection=RCC_USART16CLKSOURCE_PLL2
RCC.USART234578CLockSelection=RCC_USART234578CLKSOURCE_PLL2
RCC.USBCLockSelection=RCC_USBCLKSOURCE_PLL3
RCC.USBFreq_Value=48000000
SH.ADCx_INP10.0=ADC3_INP10,IN10-Single-Ended
SH.ADCx_INP11.0=ADC3_INP11,IN11-Single-Ended
SH.ADCx_INP14.0=ADC1_INP14,IN14-Single-Ended
SH.ADCx_INP15.0=ADC1_INP15,IN15-Single-Ended
SH.ADCx_INP18.0=ADC1_INP18,IN18-Single-Ended
SH.ADCx_INP3.0=ADC1_INP3,IN3-Single-Ended
SH.ADCx_INP4.0=ADC1_INP4,IN4-Single-Ended
SH.ADCx_INP8.0=ADC1_INP8,IN8-Single-Ended
SH.S_TIM1_CH1.0=TIM1_CH1,PWM Generation1 CH1 CH1N
SH.S_TIM1_CH2.0=TIM1_CH2,PWM Generation2 CH2 CH2N
SH.S_TIM1_CH3.0=TIM1_CH3,PWM Generation3 CH3 CH3N
SH.S_TIM2_CH1_ETR.0=TIM2_CH1,PWM_Input_1
SH.S_TIM3_CH1.0=TIM3_CH1,Encoder_Interface
SH.S_TIM3_CH2.0=TIM3_CH2,Encoder_Interface
SH.S_TIM3_CH3.0=TIM3_CH3,Input_Capture3_from_TI3
SH.S_TIM4_CH1.0=TIM4_CH1,Encoder_Interface
SH.S_TIM4_CH2.0=TIM4_CH2,Encoder_Interface
SH.S_TIM4_CH3.0=TIM4_CH3,Input_Capture3_from_TI3
SH.S_TIM5_CH1.0=TIM5_CH1,PWM_Input_1
SH.S_TIM8_CH1.0=TIM8_CH1,PWM Generation1 CH1 CH1N
SH.S_TIM8_CH2.0=TIM8_CH2,PWM Generation2 CH2 CH2N
SH.S_TIM8_CH3.0=TIM8_CH3,PWM Generation3 CH3 CH3N
SPI2.BaudRatePrescaler=SPI_BAUDRATEPRESCALER_64
SPI2.CLKPhase=SPI_PHASE_2EDGE
SPI2.CalculateBaudRate=1000.0 KBits/s
SPI2.DataSize=SPI_DATASIZE_16BIT
SPI2.Direction=SPI_DIRECTION_2LINES
SPI2.Mode=SPI_MODE_MASTER
SPI2.VirtualType=VM_MASTER
TIM1.AutoReloadPreload=TIM_AUTORELOAD_PRELOAD_ENABLE
TIM1.Channel-PWM\ Generation1\ CH1\ CH1N=TIM_CHANNEL_1
TIM1.Channel-PWM\ Generation2\ CH2\ CH2N=TIM_CHANNEL_2
TIM1.Channel-PWM\ Generation3\ CH3\ CH3N=TIM_CHANNEL_3
TIM1.CounterMode=TIM_COUNTERMODE_CENTERALIGNED3
TIM1.OCMode_PWM-PWM\ Generation1\ CH1\ CH1N=TIM_OCMODE_PWM2
TIM1.OCMode_PWM-PWM\ Generation2\ CH2\ CH2N=TIM_OCMODE_PWM2
TIM1.OCMode_PWM-PWM\ Generation3\ CH3\ CH3N=TIM_OCMODE_PWM2
TIM1.Period=TIM1_PERIOD_CLOCKS
TIM1.Pulse-PWM\ Generation1\ CH1\ CH1N=TIM1_PERIOD_CLOCKS/2
TIM1.Pulse-PWM\ Generation2\ CH2\ CH2N=TIM1_PERIOD_CLOCKS/2
TIM1.Pulse-PWM\ Generation3\ CH3\ CH3N=TIM1_PERIOD_CLOCKS/2
TIM1.RepetitionCounter=TIM1_RCR
TIM1.TIM_MasterOutputTrigger=TIM_TRGO_ENABLE
TIM1.TIM_MasterOutputTrigger2=TIM_TRGO2_UPDATE
TIM3.Channel-Input_Capture3_from_TI3=TIM_CHANNEL_3
TIM4.Channel-Input_Capture3_from_TI3=TIM_CHANNEL_3
TIM8.Channel-PWM\ Generation1\ CH1\ CH1N=TIM_CHANNEL_1
TIM8.Channel-PWM\ Generation2\ CH2\ CH2N=TIM_CHANNEL_2
TIM8.Channel-PWM\ Generation3\ CH3\ CH3N=TIM_CHANNEL_3
TIM8.CounterMode=TIM_COUNTERMODE_CENTERALIGNED3
TIM8.OCMode_PWM-PWM\ Generation1\ CH1\ CH1N=TIM_OCMODE_PWM2
TIM8.OCMode_PWM-PWM\ Generation2\ CH2\ CH2N=TIM_OCMODE_PWM2
TIM8.OCMode_PWM-PWM\ Generation3\ CH3\ CH3N=TIM_OCMODE_PWM2
TIM8.Period=TIM1_PERIOD_CLOCKS
TIM8.Pulse-PWM\ Generation1\ CH1\ CH1N=TIM1_PERIOD_CLOCKS/2
TIM8.Pulse-PWM\ Generation2\ CH2\ CH2N=TIM1_PERIOD_CLOCKS/2
TIM8.Pulse-PWM\ Generation3\ CH3\ CH3N=TIM1_PERIOD_CLOCKS/2
TIM8.RepetitionCounter=TIM1_RCR
TIM8.TIM_MasterOutputTrigger=TIM_TRGO_ENABLE
TIM8.TIM_MasterOutputTrigger2=TIM_TRGO2_UPDATE
USART1.OverSampling=UART_OVERSAMPLING_16
USART1.VirtualMode-Asynchronous=VM_ASYNC
USART2.BaudRate=2500000
USART2.VirtualMode-Asynchronous=VM_ASYNC
USART2.VirtualMode-Hardware\ Flow\ Control\ (RS485)=VM_ASYNC
USART3.BaudRate=2500000
USART3.VirtualMode-Asynchronous=VM_ASYNC
USART3.VirtualMode-Hardware\ Flow\ Control\ (RS485)=VM_ASYNC
USB_DEVICE.CLASS_NAME_FS=CDC
USB_DEVICE.VirtualMode-CDC_FS=Cdc
USB_DEVICE.VirtualModeFS=Cdc_FS
USB_OTG_FS.VirtualMode=Device_Only
VP_FREERTOS_VS_CMSIS_V2.Mode=CMSIS_V2
VP_SYS_VS_tim7.Mode=TIM7
VP_TIM12_VS_ClockSourceINT.Mode=Internal
VP_TIM1_VS_ClockSourceINT.Mode=Internal
VP_TIM2_VS_ClockSourceINT.Mode=Internal
VP_TIM5_VS_ClockSourceINT.Mode=Internal
VP_TIM8_VS_ClockSourceINT.Mode=Internal
VP_TIM8_VS_ClockSourceITR.Mode=TriggerSource_ITR0
VP_TIM8_VS_ControllerModeTrigger.Mode=Trigger Mode
VP_USB_DEVICE_VS_USB_DEVICE_CDC_FS.Mode=CDC_FS
board=custom

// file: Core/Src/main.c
/* USER CODE BEGIN Header */
/**
  ******************************************************************************
  * @file           : main.c
  * @brief          : Main program body
  ******************************************************************************
  * @attention
  *
  * Copyright (c) 2024 STMicroelectronics.
  * All rights reserved.
  *
  * This software is licensed under terms that can be found in the LICENSE file
  * in the root directory of this software component.
  * If no LICENSE file comes with this software, it is provided AS-IS.
  *
  ******************************************************************************
  */
/* USER CODE END Header */
#include "main.h"
#include "cmsis_os.h"
#include "usb_device.h"

/* USER CODE BEGIN Includes */
#include "application/appmain.h"
/* USER CODE END Includes */

/* USER CODE BEGIN PD */
void SD_TIM2_PeriodElapsedCallback(TIM_HandleTypeDef *htim);
void SD_TIM5_PeriodElapsedCallback(TIM_HandleTypeDef *htim);
/* USER CODE END PD */

ADC_HandleTypeDef hadc1;
ADC_HandleTypeDef hadc3;
DMA_HandleTypeDef hdma_adc1;
DMA_HandleTypeDef hdma_adc3;

FDCAN_HandleTypeDef hfdcan1;

SPI_HandleTypeDef hspi2;

TIM_HandleTypeDef htim1;
TIM_HandleTypeDef htim2;
TIM_HandleTypeDef htim3;
TIM_HandleTypeDef htim4;
TIM_HandleTypeDef htim5;
TIM_HandleTypeDef htim8;
TIM_HandleTypeDef htim12;

UART_HandleTypeDef huart4;
UART_HandleTypeDef huart8;
UART_HandleTypeDef huart1;
UART_HandleTypeDef huart2;
UART_HandleTypeDef huart3;
DMA_HandleTypeDef hdma_uart4_tx;
DMA_HandleTypeDef hdma_uart4_rx;
DMA_HandleTypeDef hdma_uart8_tx;
DMA_HandleTypeDef hdma_uart8_rx;
DMA_HandleTypeDef hdma_usart1_tx;
DMA_HandleTypeDef hdma_usart1_rx;
DMA_HandleTypeDef hdma_usart2_rx;
DMA_HandleTypeDef hdma_usart3_rx;

/* Definitions for defaultTask */
osThreadId_t defaultTaskHandle;
const osThreadAttr_t defaultTask_attributes = {
  .name = "defaultTask",
  .stack_size = 2048 * 4,
  .priority = (osPriority_t) osPriorityNormal,
};
/* USER CODE BEGIN PV */

struct _reent* _impure_data_ptr = NULL;

/* USER CODE END PV */

void SystemClock_Config(void);
void PeriphCommonClock_Config(void);
static void MX_GPIO_Init(void);
static void MX_DMA_Init(void);
static void MX_FDCAN1_Init(void);
static void MX_SPI2_Init(void);
static void MX_TIM1_Init(void);
static void MX_TIM2_Init(void);
static void MX_TIM3_Init(void);
static void MX_TIM4_Init(void);
static void MX_TIM5_Init(void);
static void MX_TIM8_Init(void);
static void MX_UART4_Init(void);
static void MX_UART8_Init(void);
static void MX_USART1_UART_Init(void);
static void MX_USART2_UART_Init(void);
static void MX_USART3_UART_Init(void);
static void MX_ADC1_Init(void);
static void MX_ADC3_Init(void);
static void MX_TIM12_Init(void);
void StartDefaultTask(void *argument);

int main(void)
{
  /* USER CODE BEGIN 1 */
  SCB_InvalidateICache();

  /* USER CODE END 1 */

  /* MCU Configuration--------------------------------------------------------*/

  /* Reset of all peripherals, Initializes the Flash interface and the Systick. */
  HAL_Init();

  /* Configure the system clock */
  SystemClock_Config();

/* Configure the peripherals common clocks */
  PeriphCommonClock_Config();

  /* Initialize all configured peripherals */
  MX_GPIO_Init();
  MX_DMA_Init();
  MX_FDCAN1_Init();
  MX_SPI2_Init();
  MX_TIM1_Init();
  MX_TIM2_Init();
  MX_TIM3_Init();
  MX_TIM4_Init();
  MX_TIM5_Init();
  MX_TIM8_Init();
  MX_UART4_Init();
  MX_UART8_Init();
  MX_USART1_UART_Init();
  MX_USART2_UART_Init();
  MX_USART3_UART_Init();
  MX_ADC1_Init();
  MX_ADC3_Init();
  MX_TIM12_Init();
  /* USER CODE BEGIN 2 */
  HAL_GPIO_WritePin(LED_STATUS_GPIO_Port, LED_STATUS_Pin, GPIO_PIN_SET);
  HAL_GPIO_WritePin(LED_WARN_GPIO_Port, LED_WARN_Pin, GPIO_PIN_SET);

  /*
   * Save the original newlib _reent context
   */
  _impure_data_ptr = _impure_ptr;

  /* USER CODE END 2 */

  /* Init scheduler */
  osKernelInitialize();

  /* Create the thread(s) */
  /* creation of defaultTask */
  defaultTaskHandle = osThreadNew(StartDefaultTask, NULL, &defaultTask_attributes);

  /* Start scheduler */
  osKernelStart();

  /* We should never get here as control is now taken by the scheduler */
  /* Infinite loop */
  while (1)
  {

  }
}

void SystemClock_Config(void)
{
  RCC_OscInitTypeDef RCC_OscInitStruct = {0};
  RCC_ClkInitTypeDef RCC_ClkInitStruct = {0};

  /** Supply configuration update enable
  */
  HAL_PWREx_ConfigSupply(PWR_LDO_SUPPLY);

  /** Configure the main internal regulator output voltage
  */
  __HAL_PWR_VOLTAGESCALING_CONFIG(PWR_REGULATOR_VOLTAGE_SCALE1);

  while(!__HAL_PWR_GET_FLAG(PWR_FLAG_VOSRDY)) {}

  __HAL_RCC_SYSCFG_CLK_ENABLE();
  __HAL_PWR_VOLTAGESCALING_CONFIG(PWR_REGULATOR_VOLTAGE_SCALE0);

  while(!__HAL_PWR_GET_FLAG(PWR_FLAG_VOSRDY)) {}

  /** Initializes the RCC Oscillators according to the specified parameters
  * in the RCC_OscInitTypeDef structure.
  */
  RCC_OscInitStruct.OscillatorType = RCC_OSCILLATORTYPE_HSI|RCC_OSCILLATORTYPE_HSE;
  RCC_OscInitStruct.HSEState = RCC_HSE_ON;
  RCC_OscInitStruct.HSIState = RCC_HSI_DIV1;
  RCC_OscInitStruct.HSICalibrationValue = RCC_HSICALIBRATION_DEFAULT;
  RCC_OscInitStruct.PLL.PLLState = RCC_PLL_ON;
  RCC_OscInitStruct.PLL.PLLSource = RCC_PLLSOURCE_HSE;
  RCC_OscInitStruct.PLL.PLLM = 3;
  RCC_OscInitStruct.PLL.PLLN = 240;
  RCC_OscInitStruct.PLL.PLLP = 2;
  RCC_OscInitStruct.PLL.PLLQ = 7;
  RCC_OscInitStruct.PLL.PLLR = 2;
  RCC_OscInitStruct.PLL.PLLRGE = RCC_PLL1VCIRANGE_2;
  RCC_OscInitStruct.PLL.PLLVCOSEL = RCC_PLL1VCOWIDE;
  RCC_OscInitStruct.PLL.PLLFRACN = 0;
  if (HAL_RCC_OscConfig(&RCC_OscInitStruct) != HAL_OK)
  {
    Error_Handler();
  }

  /** Initializes the CPU, AHB and APB buses clocks
  */
  RCC_ClkInitStruct.ClockType = RCC_CLOCKTYPE_HCLK|RCC_CLOCKTYPE_SYSCLK
                              |RCC_CLOCKTYPE_PCLK1|RCC_CLOCKTYPE_PCLK2
                              |RCC_CLOCKTYPE_D3PCLK1|RCC_CLOCKTYPE_D1PCLK1;
  RCC_ClkInitStruct.SYSCLKSource = RCC_SYSCLKSOURCE_PLLCLK;
  RCC_ClkInitStruct.SYSCLKDivider = RCC_SYSCLK_DIV1;
  RCC_ClkInitStruct.AHBCLKDivider = RCC_HCLK_DIV2;
  RCC_ClkInitStruct.APB3CLKDivider = RCC_APB3_DIV2;
  RCC_ClkInitStruct.APB1CLKDivider = RCC_APB1_DIV2;
  RCC_ClkInitStruct.APB2CLKDivider = RCC_APB2_DIV2;
  RCC_ClkInitStruct.APB4CLKDivider = RCC_APB4_DIV2;

  if (HAL_RCC_ClockConfig(&RCC_ClkInitStruct, FLASH_LATENCY_4) != HAL_OK)
  {
    Error_Handler();
  }
}

void PeriphCommonClock_Config(void)
{
  RCC_PeriphCLKInitTypeDef PeriphClkInitStruct = {0};

  /** Initializes the peripherals clock
  */
  PeriphClkInitStruct.PeriphClockSelection = RCC_PERIPHCLK_ADC|RCC_PERIPHCLK_UART8
                              |RCC_PERIPHCLK_USART1|RCC_PERIPHCLK_UART4
                              |RCC_PERIPHCLK_USART2|RCC_PERIPHCLK_CKPER
                              |RCC_PERIPHCLK_USART3;
  PeriphClkInitStruct.PLL2.PLL2M = 1;
  PeriphClkInitStruct.PLL2.PLL2N = 12;
  PeriphClkInitStruct.PLL2.PLL2P = 4;
  PeriphClkInitStruct.PLL2.PLL2Q = 3;
  PeriphClkInitStruct.PLL2.PLL2R = 2;
  PeriphClkInitStruct.PLL2.PLL2RGE = RCC_PLL2VCIRANGE_3;
  PeriphClkInitStruct.PLL2.PLL2VCOSEL = RCC_PLL2VCOMEDIUM;
  PeriphClkInitStruct.PLL2.PLL2FRACN = 4096;
  PeriphClkInitStruct.CkperClockSelection = RCC_CLKPSOURCE_HSI;
  PeriphClkInitStruct.Usart234578ClockSelection = RCC_USART234578CLKSOURCE_PLL2;
  PeriphClkInitStruct.Usart16ClockSelection = RCC_USART16CLKSOURCE_PLL2;
  PeriphClkInitStruct.AdcClockSelection = RCC_ADCCLKSOURCE_PLL2;
  if (HAL_RCCEx_PeriphCLKConfig(&PeriphClkInitStruct) != HAL_OK)
  {
    Error_Handler();
  }
}

static void MX_ADC1_Init(void)
{

  ADC_MultiModeTypeDef multimode = {0};
  ADC_ChannelConfTypeDef sConfig = {0};
  ADC_InjectionConfTypeDef sConfigInjected = {0};

  /** Common config
  */
  hadc1.Instance = ADC1;
  hadc1.Init.ClockPrescaler = ADC_CLOCK_ASYNC_DIV2;
  hadc1.Init.Resolution = ADC_RESOLUTION_16B;
  hadc1.Init.ScanConvMode = ADC_SCAN_ENABLE;
  hadc1.Init.EOCSelection = ADC_EOC_SEQ_CONV;
  hadc1.Init.LowPowerAutoWait = DISABLE;
  hadc1.Init.ContinuousConvMode = DISABLE;
  hadc1.Init.NbrOfConversion = 7;
  hadc1.Init.DiscontinuousConvMode = DISABLE;
  hadc1.Init.ExternalTrigConv = ADC_EXTERNALTRIG_T1_TRGO2;
  hadc1.Init.ExternalTrigConvEdge = ADC_EXTERNALTRIGCONVEDGE_RISINGFALLING;
  hadc1.Init.ConversionDataManagement = ADC_CONVERSIONDATA_DMA_CIRCULAR;
  hadc1.Init.Overrun = ADC_OVR_DATA_PRESERVED;
  hadc1.Init.LeftBitShift = ADC_LEFTBITSHIFT_NONE;
  hadc1.Init.OversamplingMode = DISABLE;
  if (HAL_ADC_Init(&hadc1) != HAL_OK)
  {
    Error_Handler();
  }

  /** Configure the ADC multi-mode
  */
  multimode.Mode = ADC_MODE_INDEPENDENT;
  if (HAL_ADCEx_MultiModeConfigChannel(&hadc1, &multimode) != HAL_OK)
  {
    Error_Handler();
  }

  /** Disable Injected Queue
  */
  HAL_ADCEx_DisableInjectedQueue(&hadc1);

  /** Configure Regular Channel
  */
  sConfig.Channel = ADC_CHANNEL_17;
  sConfig.Rank = ADC_REGULAR_RANK_1;
  sConfig.SamplingTime = ADC_SAMPLETIME_1CYCLE_5;
  sConfig.SingleDiff = ADC_SINGLE_ENDED;
  sConfig.OffsetNumber = ADC_OFFSET_NONE;
  sConfig.Offset = 0;
  sConfig.OffsetSignedSaturation = DISABLE;
  if (HAL_ADC_ConfigChannel(&hadc1, &sConfig) != HAL_OK)
  {
    Error_Handler();
  }

  /** Configure Regular Channel
  */
  sConfig.Channel = ADC_CHANNEL_14;
  sConfig.Rank = ADC_REGULAR_RANK_2;
  if (HAL_ADC_ConfigChannel(&hadc1, &sConfig) != HAL_OK)
  {
    Error_Handler();
  }

  /** Configure Regular Channel
  */
  sConfig.Channel = ADC_CHANNEL_18;
  sConfig.Rank = ADC_REGULAR_RANK_3;
  if (HAL_ADC_ConfigChannel(&hadc1, &sConfig) != HAL_OK)
  {
    Error_Handler();
  }

  /** Configure Regular Channel
  */
  sConfig.Channel = ADC_CHANNEL_3;
  sConfig.Rank = ADC_REGULAR_RANK_4;
  if (HAL_ADC_ConfigChannel(&hadc1, &sConfig) != HAL_OK)
  {
    Error_Handler();
  }

  /** Configure Regular Channel
  */
  sConfig.Channel = ADC_CHANNEL_4;
  sConfig.Rank = ADC_REGULAR_RANK_5;
  if (HAL_ADC_ConfigChannel(&hadc1, &sConfig) != HAL_OK)
  {
    Error_Handler();
  }

  /** Configure Regular Channel
  */
  sConfig.Channel = ADC_CHANNEL_8;
  sConfig.Rank = ADC_REGULAR_RANK_6;
  if (HAL_ADC_ConfigChannel(&hadc1, &sConfig) != HAL_OK)
  {
    Error_Handler();
  }

  /** Configure Regular Channel
  */
  sConfig.Channel = ADC_CHANNEL_15;
  sConfig.Rank = ADC_REGULAR_RANK_7;
  if (HAL_ADC_ConfigChannel(&hadc1, &sConfig) != HAL_OK)
  {
    Error_Handler();
  }

  /** Configure Injected Channel
  */
  sConfigInjected.InjectedChannel = ADC_CHANNEL_17;
  sConfigInjected.InjectedRank = ADC_INJECTED_RANK_1;
  sConfigInjected.InjectedSamplingTime = ADC_SAMPLETIME_1CYCLE_5;
  sConfigInjected.InjectedSingleDiff = ADC_SINGLE_ENDED;
  sConfigInjected.InjectedOffsetNumber = ADC_OFFSET_NONE;
  sConfigInjected.InjectedOffset = 0;
  sConfigInjected.InjectedOffsetSignedSaturation = DISABLE;
  sConfigInjected.InjectedNbrOfConversion = 3;
  sConfigInjected.InjectedDiscontinuousConvMode = DISABLE;
  sConfigInjected.AutoInjectedConv = DISABLE;
  sConfigInjected.QueueInjectedContext = DISABLE;
  sConfigInjected.ExternalTrigInjecConv = ADC_EXTERNALTRIGINJEC_T1_TRGO2;
  sConfigInjected.ExternalTrigInjecConvEdge = ADC_EXTERNALTRIGINJECCONV_EDGE_RISINGFALLING;
  sConfigInjected.InjecOversamplingMode = DISABLE;
  if (HAL_ADCEx_InjectedConfigChannel(&hadc1, &sConfigInjected) != HAL_OK)
  {
    Error_Handler();
  }

  /** Configure Injected Channel
  */
  sConfigInjected.InjectedChannel = ADC_CHANNEL_14;
  sConfigInjected.InjectedRank = ADC_INJECTED_RANK_2;
  if (HAL_ADCEx_InjectedConfigChannel(&hadc1, &sConfigInjected) != HAL_OK)
  {
    Error_Handler();
  }

  /** Configure Injected Channel
  */
  sConfigInjected.InjectedChannel = ADC_CHANNEL_18;
  sConfigInjected.InjectedRank = ADC_INJECTED_RANK_3;
  if (HAL_ADCEx_InjectedConfigChannel(&hadc1, &sConfigInjected) != HAL_OK)
  {
    Error_Handler();
  }
  /* USER CODE BEGIN ADC1_Init 2 */
  if (HAL_ADCEx_Calibration_Start(&hadc1, ADC_CALIB_OFFSET_LINEARITY, ADC_SINGLE_ENDED) != HAL_OK)
  {
    /* Calibration Error */
    Error_Handler();
  }

  /* USER CODE END ADC1_Init 2 */

}

static void MX_ADC3_Init(void)
{

  ADC_ChannelConfTypeDef sConfig = {0};
  ADC_InjectionConfTypeDef sConfigInjected = {0};

  /** Common config
  */
  hadc3.Instance = ADC3;
  hadc3.Init.ClockPrescaler = ADC_CLOCK_ASYNC_DIV2;
  hadc3.Init.Resolution = ADC_RESOLUTION_16B;
  hadc3.Init.ScanConvMode = ADC_SCAN_ENABLE;
  hadc3.Init.EOCSelection = ADC_EOC_SINGLE_CONV;
  hadc3.Init.LowPowerAutoWait = DISABLE;
  hadc3.Init.ContinuousConvMode = DISABLE;
  hadc3.Init.NbrOfConversion = 3;
  hadc3.Init.DiscontinuousConvMode = DISABLE;
  hadc3.Init.ExternalTrigConv = ADC_EXTERNALTRIG_T8_TRGO2;
  hadc3.Init.ExternalTrigConvEdge = ADC_EXTERNALTRIGCONVEDGE_RISING;
  hadc3.Init.ConversionDataManagement = ADC_CONVERSIONDATA_DMA_CIRCULAR;
  hadc3.Init.Overrun = ADC_OVR_DATA_PRESERVED;
  hadc3.Init.LeftBitShift = ADC_LEFTBITSHIFT_NONE;
  hadc3.Init.OversamplingMode = DISABLE;
  if (HAL_ADC_Init(&hadc3) != HAL_OK)
  {
    Error_Handler();
  }

  /** Disable Injected Queue
  */
  HAL_ADCEx_DisableInjectedQueue(&hadc3);

  /** Configure Regular Channel
  */
  sConfig.Channel = ADC_CHANNEL_10;
  sConfig.Rank = ADC_REGULAR_RANK_1;
  sConfig.SamplingTime = ADC_SAMPLETIME_1CYCLE_5;
  sConfig.SingleDiff = ADC_SINGLE_ENDED;
  sConfig.OffsetNumber = ADC_OFFSET_NONE;
  sConfig.Offset = 0;
  sConfig.OffsetSignedSaturation = DISABLE;
  if (HAL_ADC_ConfigChannel(&hadc3, &sConfig) != HAL_OK)
  {
    Error_Handler();
  }

  /** Configure Regular Channel
  */
  sConfig.Channel = ADC_CHANNEL_11;
  sConfig.Rank = ADC_REGULAR_RANK_2;
  if (HAL_ADC_ConfigChannel(&hadc3, &sConfig) != HAL_OK)
  {
    Error_Handler();
  }

  /** Configure Regular Channel
  */
  sConfig.Channel = ADC_CHANNEL_1;
  sConfig.Rank = ADC_REGULAR_RANK_3;
  if (HAL_ADC_ConfigChannel(&hadc3, &sConfig) != HAL_OK)
  {
    Error_Handler();
  }

  /** Configure Injected Channel
  */
  sConfigInjected.InjectedChannel = ADC_CHANNEL_10;
  sConfigInjected.InjectedRank = ADC_INJECTED_RANK_1;
  sConfigInjected.InjectedSamplingTime = ADC_SAMPLETIME_1CYCLE_5;
  sConfigInjected.InjectedSingleDiff = ADC_SINGLE_ENDED;
  sConfigInjected.InjectedOffsetNumber = ADC_OFFSET_NONE;
  sConfigInjected.InjectedOffset = 0;
  sConfigInjected.InjectedOffsetSignedSaturation = DISABLE;
  sConfigInjected.InjectedNbrOfConversion = 3;
  sConfigInjected.InjectedDiscontinuousConvMode = DISABLE;
  sConfigInjected.AutoInjectedConv = DISABLE;
  sConfigInjected.QueueInjectedContext = DISABLE;
  sConfigInjected.ExternalTrigInjecConv = ADC_EXTERNALTRIGINJEC_T8_TRGO2;
  sConfigInjected.ExternalTrigInjecConvEdge = ADC_EXTERNALTRIGINJECCONV_EDGE_RISINGFALLING;
  sConfigInjected.InjecOversamplingMode = DISABLE;
  if (HAL_ADCEx_InjectedConfigChannel(&hadc3, &sConfigInjected) != HAL_OK)
  {
    Error_Handler();
  }

  /** Configure Injected Channel
  */
  sConfigInjected.InjectedChannel = ADC_CHANNEL_11;
  sConfigInjected.InjectedRank = ADC_INJECTED_RANK_2;
  if (HAL_ADCEx_InjectedConfigChannel(&hadc3, &sConfigInjected) != HAL_OK)
  {
    Error_Handler();
  }

  /** Configure Injected Channel
  */
  sConfigInjected.InjectedChannel = ADC_CHANNEL_1;
  sConfigInjected.InjectedRank = ADC_INJECTED_RANK_3;
  if (HAL_ADCEx_InjectedConfigChannel(&hadc3, &sConfigInjected) != HAL_OK)
  {
    Error_Handler();
  }
  /* USER CODE BEGIN ADC3_Init 2 */
  if (HAL_ADCEx_Calibration_Start(&hadc3, ADC_CALIB_OFFSET_LINEARITY, ADC_SINGLE_ENDED) != HAL_OK)
  {
    /* Calibration Error */
    Error_Handler();
  }

  /* USER CODE END ADC3_Init 2 */

}

static void MX_FDCAN1_Init(void)
{

  hfdcan1.Instance = FDCAN1;
  hfdcan1.Init.FrameFormat = FDCAN_FRAME_CLASSIC;
  hfdcan1.Init.Mode = FDCAN_MODE_NORMAL;
  hfdcan1.Init.AutoRetransmission = DISABLE;
  hfdcan1.Init.TransmitPause = DISABLE;
  hfdcan1.Init.ProtocolException = DISABLE;
  hfdcan1.Init.NominalPrescaler = 16;
  hfdcan1.Init.NominalSyncJumpWidth = 1;
  hfdcan1.Init.NominalTimeSeg1 = 2;
  hfdcan1.Init.NominalTimeSeg2 = 2;
  hfdcan1.Init.DataPrescaler = 1;
  hfdcan1.Init.DataSyncJumpWidth = 1;
  hfdcan1.Init.DataTimeSeg1 = 1;
  hfdcan1.Init.DataTimeSeg2 = 1;
  hfdcan1.Init.MessageRAMOffset = 0;
  hfdcan1.Init.StdFiltersNbr = 0;
  hfdcan1.Init.ExtFiltersNbr = 0;
  hfdcan1.Init.RxFifo0ElmtsNbr = 0;
  hfdcan1.Init.RxFifo0ElmtSize = FDCAN_DATA_BYTES_8;
  hfdcan1.Init.RxFifo1ElmtsNbr = 0;
  hfdcan1.Init.RxFifo1ElmtSize = FDCAN_DATA_BYTES_8;
  hfdcan1.Init.RxBuffersNbr = 0;
  hfdcan1.Init.RxBufferSize = FDCAN_DATA_BYTES_8;
  hfdcan1.Init.TxEventsNbr = 0;
  hfdcan1.Init.TxBuffersNbr = 0;
  hfdcan1.Init.TxFifoQueueElmtsNbr = 0;
  hfdcan1.Init.TxFifoQueueMode = FDCAN_TX_FIFO_OPERATION;
  hfdcan1.Init.TxElmtSize = FDCAN_DATA_BYTES_8;
  if (HAL_FDCAN_Init(&hfdcan1) != HAL_OK)
  {
    Error_Handler();
  }

}

static void MX_SPI2_Init(void)
{

  /* SPI2 parameter configuration*/
  hspi2.Instance = SPI2;
  hspi2.Init.Mode = SPI_MODE_MASTER;
  hspi2.Init.Direction = SPI_DIRECTION_2LINES;
  hspi2.Init.DataSize = SPI_DATASIZE_16BIT;
  hspi2.Init.CLKPolarity = SPI_POLARITY_LOW;
  hspi2.Init.CLKPhase = SPI_PHASE_2EDGE;
  hspi2.Init.NSS = SPI_NSS_SOFT;
  hspi2.Init.BaudRatePrescaler = SPI_BAUDRATEPRESCALER_64;
  hspi2.Init.FirstBit = SPI_FIRSTBIT_MSB;
  hspi2.Init.TIMode = SPI_TIMODE_DISABLE;
  hspi2.Init.CRCCalculation = SPI_CRCCALCULATION_DISABLE;
  hspi2.Init.CRCPolynomial = 0x0;
  hspi2.Init.NSSPMode = SPI_NSS_PULSE_ENABLE;
  hspi2.Init.NSSPolarity = SPI_NSS_POLARITY_LOW;
  hspi2.Init.FifoThreshold = SPI_FIFO_THRESHOLD_01DATA;
  hspi2.Init.TxCRCInitializationPattern = SPI_CRC_INITIALIZATION_ALL_ZERO_PATTERN;
  hspi2.Init.RxCRCInitializationPattern = SPI_CRC_INITIALIZATION_ALL_ZERO_PATTERN;
  hspi2.Init.MasterSSIdleness = SPI_MASTER_SS_IDLENESS_00CYCLE;
  hspi2.Init.MasterInterDataIdleness = SPI_MASTER_INTERDATA_IDLENESS_00CYCLE;
  hspi2.Init.MasterReceiverAutoSusp = SPI_MASTER_RX_AUTOSUSP_DISABLE;
  hspi2.Init.MasterKeepIOState = SPI_MASTER_KEEP_IO_STATE_DISABLE;
  hspi2.Init.IOSwap = SPI_IO_SWAP_DISABLE;
  if (HAL_SPI_Init(&hspi2) != HAL_OK)
  {
    Error_Handler();
  }

}

static void MX_TIM1_Init(void)
{

  TIM_ClockConfigTypeDef sClockSourceConfig = {0};
  TIM_MasterConfigTypeDef sMasterConfig = {0};
  TIM_OC_InitTypeDef sConfigOC = {0};
  TIM_BreakDeadTimeConfigTypeDef sBreakDeadTimeConfig = {0};

  htim1.Instance = TIM1;
  htim1.Init.Prescaler = 0;
  htim1.Init.CounterMode = TIM_COUNTERMODE_CENTERALIGNED3;
  htim1.Init.Period = TIM1_PERIOD_CLOCKS;
  htim1.Init.ClockDivision = TIM_CLOCKDIVISION_DIV1;
  htim1.Init.RepetitionCounter = TIM1_RCR;
  htim1.Init.AutoReloadPreload = TIM_AUTORELOAD_PRELOAD_ENABLE;
  if (HAL_TIM_Base_Init(&htim1) != HAL_OK)
  {
    Error_Handler();
  }
  sClockSourceConfig.ClockSource = TIM_CLOCKSOURCE_INTERNAL;
  if (HAL_TIM_ConfigClockSource(&htim1, &sClockSourceConfig) != HAL_OK)
  {
    Error_Handler();
  }
  if (HAL_TIM_PWM_Init(&htim1) != HAL_OK)
  {
    Error_Handler();
  }
  sMasterConfig.MasterOutputTrigger = TIM_TRGO_ENABLE;
  sMasterConfig.MasterOutputTrigger2 = TIM_TRGO2_UPDATE;
  sMasterConfig.MasterSlaveMode = TIM_MASTERSLAVEMODE_DISABLE;
  if (HAL_TIMEx_MasterConfigSynchronization(&htim1, &sMasterConfig) != HAL_OK)
  {
    Error_Handler();
  }
  sConfigOC.OCMode = TIM_OCMODE_PWM2;
  sConfigOC.Pulse = TIM1_PERIOD_CLOCKS/2;
  sConfigOC.OCPolarity = TIM_OCPOLARITY_HIGH;
  sConfigOC.OCNPolarity = TIM_OCNPOLARITY_HIGH;
  sConfigOC.OCFastMode = TIM_OCFAST_DISABLE;
  sConfigOC.OCIdleState = TIM_OCIDLESTATE_RESET;
  sConfigOC.OCNIdleState = TIM_OCNIDLESTATE_RESET;
  if (HAL_TIM_PWM_ConfigChannel(&htim1, &sConfigOC, TIM_CHANNEL_1) != HAL_OK)
  {
    Error_Handler();
  }
  if (HAL_TIM_PWM_ConfigChannel(&htim1, &sConfigOC, TIM_CHANNEL_2) != HAL_OK)
  {
    Error_Handler();
  }
  if (HAL_TIM_PWM_ConfigChannel(&htim1, &sConfigOC, TIM_CHANNEL_3) != HAL_OK)
  {
    Error_Handler();
  }
  sBreakDeadTimeConfig.OffStateRunMode = TIM_OSSR_DISABLE;
  sBreakDeadTimeConfig.OffStateIDLEMode = TIM_OSSI_DISABLE;
  sBreakDeadTimeConfig.LockLevel = TIM_LOCKLEVEL_OFF;
  sBreakDeadTimeConfig.DeadTime = 0;
  sBreakDeadTimeConfig.BreakState = TIM_BREAK_DISABLE;
  sBreakDeadTimeConfig.BreakPolarity = TIM_BREAKPOLARITY_HIGH;
  sBreakDeadTimeConfig.BreakFilter = 0;
  sBreakDeadTimeConfig.Break2State = TIM_BREAK2_DISABLE;
  sBreakDeadTimeConfig.Break2Polarity = TIM_BREAK2POLARITY_HIGH;
  sBreakDeadTimeConfig.Break2Filter = 0;
  sBreakDeadTimeConfig.AutomaticOutput = TIM_AUTOMATICOUTPUT_DISABLE;
  if (HAL_TIMEx_ConfigBreakDeadTime(&htim1, &sBreakDeadTimeConfig) != HAL_OK)
  {
    Error_Handler();
  }
  HAL_TIM_MspPostInit(&htim1);

}

static void MX_TIM2_Init(void)
{

  TIM_ClockConfigTypeDef sClockSourceConfig = {0};
  TIM_SlaveConfigTypeDef sSlaveConfig = {0};
  TIM_IC_InitTypeDef sConfigIC = {0};
  TIM_MasterConfigTypeDef sMasterConfig = {0};

  htim2.Instance = TIM2;
  htim2.Init.Prescaler = 0;
  htim2.Init.CounterMode = TIM_COUNTERMODE_UP;
  htim2.Init.Period = 4294967295;
  htim2.Init.ClockDivision = TIM_CLOCKDIVISION_DIV1;
  htim2.Init.AutoReloadPreload = TIM_AUTORELOAD_PRELOAD_DISABLE;
  if (HAL_TIM_Base_Init(&htim2) != HAL_OK)
  {
    Error_Handler();
  }
  sClockSourceConfig.ClockSource = TIM_CLOCKSOURCE_INTERNAL;
  if (HAL_TIM_ConfigClockSource(&htim2, &sClockSourceConfig) != HAL_OK)
  {
    Error_Handler();
  }
  if (HAL_TIM_IC_Init(&htim2) != HAL_OK)
  {
    Error_Handler();
  }
  sSlaveConfig.SlaveMode = TIM_SLAVEMODE_RESET;
  sSlaveConfig.InputTrigger = TIM_TS_TI1FP1;
  sSlaveConfig.TriggerPolarity = TIM_INPUTCHANNELPOLARITY_RISING;
  sSlaveConfig.TriggerPrescaler = TIM_ICPSC_DIV1;
  sSlaveConfig.TriggerFilter = 0;
  if (HAL_TIM_SlaveConfigSynchro(&htim2, &sSlaveConfig) != HAL_OK)
  {
    Error_Handler();
  }
  sConfigIC.ICPolarity = TIM_INPUTCHANNELPOLARITY_RISING;
  sConfigIC.ICSelection = TIM_ICSELECTION_DIRECTTI;
  sConfigIC.ICPrescaler = TIM_ICPSC_DIV1;
  sConfigIC.ICFilter = 0;
  if (HAL_TIM_IC_ConfigChannel(&htim2, &sConfigIC, TIM_CHANNEL_1) != HAL_OK)
  {
    Error_Handler();
  }
  sConfigIC.ICPolarity = TIM_INPUTCHANNELPOLARITY_FALLING;
  sConfigIC.ICSelection = TIM_ICSELECTION_INDIRECTTI;
  if (HAL_TIM_IC_ConfigChannel(&htim2, &sConfigIC, TIM_CHANNEL_2) != HAL_OK)
  {
    Error_Handler();
  }
  sMasterConfig.MasterOutputTrigger = TIM_TRGO_RESET;
  sMasterConfig.MasterSlaveMode = TIM_MASTERSLAVEMODE_DISABLE;
  if (HAL_TIMEx_MasterConfigSynchronization(&htim2, &sMasterConfig) != HAL_OK)
  {
    Error_Handler();
  }

}

static void MX_TIM3_Init(void)
{

  TIM_Encoder_InitTypeDef sConfig = {0};
  TIM_MasterConfigTypeDef sMasterConfig = {0};
  TIM_IC_InitTypeDef sConfigIC = {0};

  htim3.Instance = TIM3;
  htim3.Init.Prescaler = 0;
  htim3.Init.CounterMode = TIM_COUNTERMODE_UP;
  htim3.Init.Period = 65535;
  htim3.Init.ClockDivision = TIM_CLOCKDIVISION_DIV1;
  htim3.Init.AutoReloadPreload = TIM_AUTORELOAD_PRELOAD_DISABLE;
  if (HAL_TIM_IC_Init(&htim3) != HAL_OK)
  {
    Error_Handler();
  }
  sConfig.EncoderMode = TIM_ENCODERMODE_TI1;
  sConfig.IC1Polarity = TIM_ICPOLARITY_RISING;
  sConfig.IC1Selection = TIM_ICSELECTION_DIRECTTI;
  sConfig.IC1Prescaler = TIM_ICPSC_DIV1;
  sConfig.IC1Filter = 0;
  sConfig.IC2Polarity = TIM_ICPOLARITY_RISING;
  sConfig.IC2Selection = TIM_ICSELECTION_DIRECTTI;
  sConfig.IC2Prescaler = TIM_ICPSC_DIV1;
  sConfig.IC2Filter = 0;
  if (HAL_TIM_Encoder_Init(&htim3, &sConfig) != HAL_OK)
  {
    Error_Handler();
  }
  sMasterConfig.MasterOutputTrigger = TIM_TRGO_RESET;
  sMasterConfig.MasterSlaveMode = TIM_MASTERSLAVEMODE_DISABLE;
  if (HAL_TIMEx_MasterConfigSynchronization(&htim3, &sMasterConfig) != HAL_OK)
  {
    Error_Handler();
  }
  sConfigIC.ICPolarity = TIM_INPUTCHANNELPOLARITY_RISING;
  sConfigIC.ICSelection = TIM_ICSELECTION_DIRECTTI;
  sConfigIC.ICPrescaler = TIM_ICPSC_DIV1;
  sConfigIC.ICFilter = 0;
  if (HAL_TIM_IC_ConfigChannel(&htim3, &sConfigIC, TIM_CHANNEL_3) != HAL_OK)
  {
    Error_Handler();
  }

}

static void MX_TIM4_Init(void)
{

  TIM_Encoder_InitTypeDef sConfig = {0};
  TIM_MasterConfigTypeDef sMasterConfig = {0};
  TIM_IC_InitTypeDef sConfigIC = {0};

  htim4.Instance = TIM4;
  htim4.Init.Prescaler = 0;
  htim4.Init.CounterMode = TIM_COUNTERMODE_UP;
  htim4.Init.Period = 65535;
  htim4.Init.ClockDivision = TIM_CLOCKDIVISION_DIV1;
  htim4.Init.AutoReloadPreload = TIM_AUTORELOAD_PRELOAD_DISABLE;
  if (HAL_TIM_IC_Init(&htim4) != HAL_OK)
  {
    Error_Handler();
  }
  sConfig.EncoderMode = TIM_ENCODERMODE_TI1;
  sConfig.IC1Polarity = TIM_ICPOLARITY_RISING;
  sConfig.IC1Selection = TIM_ICSELECTION_DIRECTTI;
  sConfig.IC1Prescaler = TIM_ICPSC_DIV1;
  sConfig.IC1Filter = 0;
  sConfig.IC2Polarity = TIM_ICPOLARITY_RISING;
  sConfig.IC2Selection = TIM_ICSELECTION_DIRECTTI;
  sConfig.IC2Prescaler = TIM_ICPSC_DIV1;
  sConfig.IC2Filter = 0;
  if (HAL_TIM_Encoder_Init(&htim4, &sConfig) != HAL_OK)
  {
    Error_Handler();
  }
  sMasterConfig.MasterOutputTrigger = TIM_TRGO_RESET;
  sMasterConfig.MasterSlaveMode = TIM_MASTERSLAVEMODE_DISABLE;
  if (HAL_TIMEx_MasterConfigSynchronization(&htim4, &sMasterConfig) != HAL_OK)
  {
    Error_Handler();
  }
  sConfigIC.ICPolarity = TIM_INPUTCHANNELPOLARITY_RISING;
  sConfigIC.ICSelection = TIM_ICSELECTION_DIRECTTI;
  sConfigIC.ICPrescaler = TIM_ICPSC_DIV1;
  sConfigIC.ICFilter = 0;
  if (HAL_TIM_IC_ConfigChannel(&htim4, &sConfigIC, TIM_CHANNEL_3) != HAL_OK)
  {
    Error_Handler();
  }

}

static void MX_TIM5_Init(void)
{

  TIM_ClockConfigTypeDef sClockSourceConfig = {0};
  TIM_SlaveConfigTypeDef sSlaveConfig = {0};
  TIM_IC_InitTypeDef sConfigIC = {0};
  TIM_MasterConfigTypeDef sMasterConfig = {0};

  htim5.Instance = TIM5;
  htim5.Init.Prescaler = 0;
  htim5.Init.CounterMode = TIM_COUNTERMODE_UP;
  htim5.Init.Period = 4294967295;
  htim5.Init.ClockDivision = TIM_CLOCKDIVISION_DIV1;
  htim5.Init.AutoReloadPreload = TIM_AUTORELOAD_PRELOAD_DISABLE;
  if (HAL_TIM_Base_Init(&htim5) != HAL_OK)
  {
    Error_Handler();
  }
  sClockSourceConfig.ClockSource = TIM_CLOCKSOURCE_INTERNAL;
  if (HAL_TIM_ConfigClockSource(&htim5, &sClockSourceConfig) != HAL_OK)
  {
    Error_Handler();
  }
  if (HAL_TIM_IC_Init(&htim5) != HAL_OK)
  {
    Error_Handler();
  }
  sSlaveConfig.SlaveMode = TIM_SLAVEMODE_RESET;
  sSlaveConfig.InputTrigger = TIM_TS_TI1FP1;
  sSlaveConfig.TriggerPolarity = TIM_INPUTCHANNELPOLARITY_RISING;
  sSlaveConfig.TriggerPrescaler = TIM_ICPSC_DIV1;
  sSlaveConfig.TriggerFilter = 0;
  if (HAL_TIM_SlaveConfigSynchro(&htim5, &sSlaveConfig) != HAL_OK)
  {
    Error_Handler();
  }
  sConfigIC.ICPolarity = TIM_INPUTCHANNELPOLARITY_RISING;
  sConfigIC.ICSelection = TIM_ICSELECTION_DIRECTTI;
  sConfigIC.ICPrescaler = TIM_ICPSC_DIV1;
  sConfigIC.ICFilter = 0;
  if (HAL_TIM_IC_ConfigChannel(&htim5, &sConfigIC, TIM_CHANNEL_1) != HAL_OK)
  {
    Error_Handler();
  }
  sConfigIC.ICPolarity = TIM_INPUTCHANNELPOLARITY_FALLING;
  sConfigIC.ICSelection = TIM_ICSELECTION_INDIRECTTI;
  if (HAL_TIM_IC_ConfigChannel(&htim5, &sConfigIC, TIM_CHANNEL_2) != HAL_OK)
  {
    Error_Handler();
  }
  sMasterConfig.MasterOutputTrigger = TIM_TRGO_RESET;
  sMasterConfig.MasterSlaveMode = TIM_MASTERSLAVEMODE_DISABLE;
  if (HAL_TIMEx_MasterConfigSynchronization(&htim5, &sMasterConfig) != HAL_OK)
  {
    Error_Handler();
  }

}

static void MX_TIM8_Init(void)
{

  TIM_ClockConfigTypeDef sClockSourceConfig = {0};
  TIM_SlaveConfigTypeDef sSlaveConfig = {0};
  TIM_MasterConfigTypeDef sMasterConfig = {0};
  TIM_OC_InitTypeDef sConfigOC = {0};
  TIM_BreakDeadTimeConfigTypeDef sBreakDeadTimeConfig = {0};

  htim8.Instance = TIM8;
  htim8.Init.Prescaler = 0;
  htim8.Init.CounterMode = TIM_COUNTERMODE_CENTERALIGNED3;
  htim8.Init.Period = TIM1_PERIOD_CLOCKS;
  htim8.Init.ClockDivision = TIM_CLOCKDIVISION_DIV1;
  htim8.Init.RepetitionCounter = TIM1_RCR;
  htim8.Init.AutoReloadPreload = TIM_AUTORELOAD_PRELOAD_DISABLE;
  if (HAL_TIM_Base_Init(&htim8) != HAL_OK)
  {
    Error_Handler();
  }
  sClockSourceConfig.ClockSource = TIM_CLOCKSOURCE_INTERNAL;
  if (HAL_TIM_ConfigClockSource(&htim8, &sClockSourceConfig) != HAL_OK)
  {
    Error_Handler();
  }
  if (HAL_TIM_PWM_Init(&htim8) != HAL_OK)
  {
    Error_Handler();
  }
  sSlaveConfig.SlaveMode = TIM_SLAVEMODE_TRIGGER;
  sSlaveConfig.InputTrigger = TIM_TS_ITR0;
  if (HAL_TIM_SlaveConfigSynchro(&htim8, &sSlaveConfig) != HAL_OK)
  {
    Error_Handler();
  }
  sMasterConfig.MasterOutputTrigger = TIM_TRGO_ENABLE;
  sMasterConfig.MasterOutputTrigger2 = TIM_TRGO2_UPDATE;
  sMasterConfig.MasterSlaveMode = TIM_MASTERSLAVEMODE_DISABLE;
  if (HAL_TIMEx_MasterConfigSynchronization(&htim8, &sMasterConfig) != HAL_OK)
  {
    Error_Handler();
  }
  sConfigOC.OCMode = TIM_OCMODE_PWM2;
  sConfigOC.Pulse = TIM1_PERIOD_CLOCKS/2;
  sConfigOC.OCPolarity = TIM_OCPOLARITY_HIGH;
  sConfigOC.OCNPolarity = TIM_OCNPOLARITY_HIGH;
  sConfigOC.OCFastMode = TIM_OCFAST_DISABLE;
  sConfigOC.OCIdleState = TIM_OCIDLESTATE_RESET;
  sConfigOC.OCNIdleState = TIM_OCNIDLESTATE_RESET;
  if (HAL_TIM_PWM_ConfigChannel(&htim8, &sConfigOC, TIM_CHANNEL_1) != HAL_OK)
  {
    Error_Handler();
  }
  if (HAL_TIM_PWM_ConfigChannel(&htim8, &sConfigOC, TIM_CHANNEL_2) != HAL_OK)
  {
    Error_Handler();
  }
  if (HAL_TIM_PWM_ConfigChannel(&htim8, &sConfigOC, TIM_CHANNEL_3) != HAL_OK)
  {
    Error_Handler();
  }
  sBreakDeadTimeConfig.OffStateRunMode = TIM_OSSR_DISABLE;
  sBreakDeadTimeConfig.OffStateIDLEMode = TIM_OSSI_DISABLE;
  sBreakDeadTimeConfig.LockLevel = TIM_LOCKLEVEL_OFF;
  sBreakDeadTimeConfig.DeadTime = 0;
  sBreakDeadTimeConfig.BreakState = TIM_BREAK_DISABLE;
  sBreakDeadTimeConfig.BreakPolarity = TIM_BREAKPOLARITY_HIGH;
  sBreakDeadTimeConfig.BreakFilter = 0;
  sBreakDeadTimeConfig.Break2State = TIM_BREAK2_DISABLE;
  sBreakDeadTimeConfig.Break2Polarity = TIM_BREAK2POLARITY_HIGH;
  sBreakDeadTimeConfig.Break2Filter = 0;
  sBreakDeadTimeConfig.AutomaticOutput = TIM_AUTOMATICOUTPUT_DISABLE;
  if (HAL_TIMEx_ConfigBreakDeadTime(&htim8, &sBreakDeadTimeConfig) != HAL_OK)
  {
    Error_Handler();
  }
  HAL_TIM_MspPostInit(&htim8);

}

static void MX_TIM12_Init(void)
{

  TIM_ClockConfigTypeDef sClockSourceConfig = {0};
  TIM_MasterConfigTypeDef sMasterConfig = {0};

  htim12.Instance = TIM12;
  htim12.Init.Prescaler = 0;
  htim12.Init.CounterMode = TIM_COUNTERMODE_UP;
  htim12.Init.Period = 65535;
  htim12.Init.ClockDivision = TIM_CLOCKDIVISION_DIV1;
  htim12.Init.AutoReloadPreload = TIM_AUTORELOAD_PRELOAD_DISABLE;
  if (HAL_TIM_Base_Init(&htim12) != HAL_OK)
  {
    Error_Handler();
  }
  sClockSourceConfig.ClockSource = TIM_CLOCKSOURCE_INTERNAL;
  if (HAL_TIM_ConfigClockSource(&htim12, &sClockSourceConfig) != HAL_OK)
  {
    Error_Handler();
  }
  sMasterConfig.MasterOutputTrigger = TIM_TRGO_RESET;
  sMasterConfig.MasterSlaveMode = TIM_MASTERSLAVEMODE_DISABLE;
  if (HAL_TIMEx_MasterConfigSynchronization(&htim12, &sMasterConfig) != HAL_OK)
  {
    Error_Handler();
  }

}

static void MX_UART4_Init(void)
{

  huart4.Instance = UART4;
  huart4.Init.BaudRate = 115200;
  huart4.Init.WordLength = UART_WORDLENGTH_8B;
  huart4.Init.StopBits = UART_STOPBITS_1;
  huart4.Init.Parity = UART_PARITY_NONE;
  huart4.Init.Mode = UART_MODE_TX_RX;
  huart4.Init.HwFlowCtl = UART_HWCONTROL_NONE;
  huart4.Init.OverSampling = UART_OVERSAMPLING_16;
  huart4.Init.OneBitSampling = UART_ONE_BIT_SAMPLE_DISABLE;
  huart4.Init.ClockPrescaler = UART_PRESCALER_DIV1;
  huart4.AdvancedInit.AdvFeatureInit = UART_ADVFEATURE_NO_INIT;
  if (HAL_UART_Init(&huart4) != HAL_OK)
  {
    Error_Handler();
  }
  if (HAL_UARTEx_SetTxFifoThreshold(&huart4, UART_TXFIFO_THRESHOLD_1_8) != HAL_OK)
  {
    Error_Handler();
  }
  if (HAL_UARTEx_SetRxFifoThreshold(&huart4, UART_RXFIFO_THRESHOLD_1_8) != HAL_OK)
  {
    Error_Handler();
  }
  if (HAL_UARTEx_DisableFifoMode(&huart4) != HAL_OK)
  {
    Error_Handler();
  }

}

static void MX_UART8_Init(void)
{

  huart8.Instance = UART8;
  huart8.Init.BaudRate = 115200;
  huart8.Init.WordLength = UART_WORDLENGTH_8B;
  huart8.Init.StopBits = UART_STOPBITS_1;
  huart8.Init.Parity = UART_PARITY_NONE;
  huart8.Init.Mode = UART_MODE_TX_RX;
  huart8.Init.HwFlowCtl = UART_HWCONTROL_NONE;
  huart8.Init.OverSampling = UART_OVERSAMPLING_16;
  huart8.Init.OneBitSampling = UART_ONE_BIT_SAMPLE_DISABLE;
  huart8.Init.ClockPrescaler = UART_PRESCALER_DIV1;
  huart8.AdvancedInit.AdvFeatureInit = UART_ADVFEATURE_NO_INIT;
  if (HAL_UART_Init(&huart8) != HAL_OK)
  {
    Error_Handler();
  }
  if (HAL_UARTEx_SetTxFifoThreshold(&huart8, UART_TXFIFO_THRESHOLD_1_8) != HAL_OK)
  {
    Error_Handler();
  }
  if (HAL_UARTEx_SetRxFifoThreshold(&huart8, UART_RXFIFO_THRESHOLD_1_8) != HAL_OK)
  {
    Error_Handler();
  }
  if (HAL_UARTEx_DisableFifoMode(&huart8) != HAL_OK)
  {
    Error_Handler();
  }

}

static void MX_USART1_UART_Init(void)
{

  huart1.Instance = USART1;
  huart1.Init.BaudRate = 115200;
  huart1.Init.WordLength = UART_WORDLENGTH_8B;
  huart1.Init.StopBits = UART_STOPBITS_1;
  huart1.Init.Parity = UART_PARITY_NONE;
  huart1.Init.Mode = UART_MODE_TX_RX;
  huart1.Init.HwFlowCtl = UART_HWCONTROL_NONE;
  huart1.Init.OverSampling = UART_OVERSAMPLING_16;
  huart1.Init.OneBitSampling = UART_ONE_BIT_SAMPLE_DISABLE;
  huart1.Init.ClockPrescaler = UART_PRESCALER_DIV1;
  huart1.AdvancedInit.AdvFeatureInit = UART_ADVFEATURE_NO_INIT;
  if (HAL_UART_Init(&huart1) != HAL_OK)
  {
    Error_Handler();
  }
  if (HAL_UARTEx_SetTxFifoThreshold(&huart1, UART_TXFIFO_THRESHOLD_1_8) != HAL_OK)
  {
    Error_Handler();
  }
  if (HAL_UARTEx_SetRxFifoThreshold(&huart1, UART_RXFIFO_THRESHOLD_1_8) != HAL_OK)
  {
    Error_Handler();
  }
  if (HAL_UARTEx_DisableFifoMode(&huart1) != HAL_OK)
  {
    Error_Handler();
  }

}

static void MX_USART2_UART_Init(void)
{

  huart2.Instance = USART2;
  huart2.Init.BaudRate = 2500000;
  huart2.Init.WordLength = UART_WORDLENGTH_8B;
  huart2.Init.StopBits = UART_STOPBITS_1;
  huart2.Init.Parity = UART_PARITY_NONE;
  huart2.Init.Mode = UART_MODE_TX_RX;
  huart2.Init.HwFlowCtl = UART_HWCONTROL_NONE;
  huart2.Init.OverSampling = UART_OVERSAMPLING_16;
  huart2.Init.OneBitSampling = UART_ONE_BIT_SAMPLE_DISABLE;
  huart2.Init.ClockPrescaler = UART_PRESCALER_DIV1;
  huart2.AdvancedInit.AdvFeatureInit = UART_ADVFEATURE_NO_INIT;
  if (HAL_RS485Ex_Init(&huart2, UART_DE_POLARITY_HIGH, 0, 0) != HAL_OK)
  {
    Error_Handler();
  }
  if (HAL_UARTEx_SetTxFifoThreshold(&huart2, UART_TXFIFO_THRESHOLD_1_8) != HAL_OK)
  {
    Error_Handler();
  }
  if (HAL_UARTEx_SetRxFifoThreshold(&huart2, UART_RXFIFO_THRESHOLD_1_8) != HAL_OK)
  {
    Error_Handler();
  }
  if (HAL_UARTEx_DisableFifoMode(&huart2) != HAL_OK)
  {
    Error_Handler();
  }

}

static void MX_USART3_UART_Init(void)
{

  huart3.Instance = USART3;
  huart3.Init.BaudRate = 2500000;
  huart3.Init.WordLength = UART_WORDLENGTH_8B;
  huart3.Init.StopBits = UART_STOPBITS_1;
  huart3.Init.Parity = UART_PARITY_NONE;
  huart3.Init.Mode = UART_MODE_TX_RX;
  huart3.Init.HwFlowCtl = UART_HWCONTROL_NONE;
  huart3.Init.OverSampling = UART_OVERSAMPLING_16;
  huart3.Init.OneBitSampling = UART_ONE_BIT_SAMPLE_DISABLE;
  huart3.Init.ClockPrescaler = UART_PRESCALER_DIV1;
  huart3.AdvancedInit.AdvFeatureInit = UART_ADVFEATURE_NO_INIT;
  if (HAL_RS485Ex_Init(&huart3, UART_DE_POLARITY_HIGH, 0, 0) != HAL_OK)
  {
    Error_Handler();
  }
  if (HAL_UARTEx_SetTxFifoThreshold(&huart3, UART_TXFIFO_THRESHOLD_1_8) != HAL_OK)
  {
    Error_Handler();
  }
  if (HAL_UARTEx_SetRxFifoThreshold(&huart3, UART_RXFIFO_THRESHOLD_1_8) != HAL_OK)
  {
    Error_Handler();
  }
  if (HAL_UARTEx_DisableFifoMode(&huart3) != HAL_OK)
  {
    Error_Handler();
  }

}

static void MX_DMA_Init(void)
{

  /* DMA controller clock enable */
  __HAL_RCC_DMA1_CLK_ENABLE();
  __HAL_RCC_DMA2_CLK_ENABLE();

  /* DMA interrupt init */
  /* DMA1_Stream0_IRQn interrupt configuration */
  HAL_NVIC_SetPriority(DMA1_Stream0_IRQn, 5, 0);
  HAL_NVIC_EnableIRQ(DMA1_Stream0_IRQn);
  /* DMA1_Stream1_IRQn interrupt configuration */
  HAL_NVIC_SetPriority(DMA1_Stream1_IRQn, 5, 0);
  HAL_NVIC_EnableIRQ(DMA1_Stream1_IRQn);
  /* DMA1_Stream2_IRQn interrupt configuration */
  HAL_NVIC_SetPriority(DMA1_Stream2_IRQn, 5, 0);
  HAL_NVIC_EnableIRQ(DMA1_Stream2_IRQn);
  /* DMA1_Stream4_IRQn interrupt configuration */
  HAL_NVIC_SetPriority(DMA1_Stream4_IRQn, 5, 0);
  HAL_NVIC_EnableIRQ(DMA1_Stream4_IRQn);
  /* DMA1_Stream5_IRQn interrupt configuration */
  HAL_NVIC_SetPriority(DMA1_Stream5_IRQn, 5, 0);
  HAL_NVIC_EnableIRQ(DMA1_Stream5_IRQn);
  /* DMA1_Stream6_IRQn interrupt configuration */
  HAL_NVIC_SetPriority(DMA1_Stream6_IRQn, 5, 0);
  HAL_NVIC_EnableIRQ(DMA1_Stream6_IRQn);
  /* DMA2_Stream0_IRQn interrupt configuration */
  HAL_NVIC_SetPriority(DMA2_Stream0_IRQn, 5, 0);
  HAL_NVIC_EnableIRQ(DMA2_Stream0_IRQn);
  /* DMA2_Stream2_IRQn interrupt configuration */
  HAL_NVIC_SetPriority(DMA2_Stream2_IRQn, 5, 0);
  HAL_NVIC_EnableIRQ(DMA2_Stream2_IRQn);
  /* DMA2_Stream5_IRQn interrupt configuration */
  HAL_NVIC_SetPriority(DMA2_Stream5_IRQn, 5, 0);
  HAL_NVIC_EnableIRQ(DMA2_Stream5_IRQn);
  /* DMA2_Stream7_IRQn interrupt configuration */
  HAL_NVIC_SetPriority(DMA2_Stream7_IRQn, 5, 0);
  HAL_NVIC_EnableIRQ(DMA2_Stream7_IRQn);

}

static void MX_GPIO_Init(void)
{
  GPIO_InitTypeDef GPIO_InitStruct = {0};

  /* GPIO Ports Clock Enable */
  __HAL_RCC_GPIOE_CLK_ENABLE();
  __HAL_RCC_GPIOC_CLK_ENABLE();
  __HAL_RCC_GPIOH_CLK_ENABLE();
  __HAL_RCC_GPIOA_CLK_ENABLE();
  __HAL_RCC_GPIOB_CLK_ENABLE();
  __HAL_RCC_GPIOD_CLK_ENABLE();

  /*Configure GPIO pin Output Level */
  HAL_GPIO_WritePin(GPIOC, DRV1_CS_Pin|DRV2_CS_Pin|LED_STATUS_Pin|BRAKE_B_RELEASE_Pin, GPIO_PIN_RESET);

  /*Configure GPIO pin Output Level */
  HAL_GPIO_WritePin(GPIOB, GATE_M2_ENABLE_Pin|OUTPUT_1_Pin|OUTPUT_2_Pin, GPIO_PIN_RESET);

  /*Configure GPIO pin Output Level */
  HAL_GPIO_WritePin(GPIOE, DRV_CAL_Pin|GATE_M1_ENABLE_Pin, GPIO_PIN_RESET);

  /*Configure GPIO pin Output Level */
  HAL_GPIO_WritePin(LED_WARN_GPIO_Port, LED_WARN_Pin, GPIO_PIN_RESET);

  /*Configure GPIO pins : INPUT_1__Pin INPUT_2__Pin BRAKE_A_FB_Pin BRAKE_B_FB_Pin */
  GPIO_InitStruct.Pin = INPUT_1__Pin|INPUT_2__Pin|BRAKE_A_FB_Pin|BRAKE_B_FB_Pin;
  GPIO_InitStruct.Mode = GPIO_MODE_INPUT;
  GPIO_InitStruct.Pull = GPIO_NOPULL;
  HAL_GPIO_Init(GPIOE, &GPIO_InitStruct);

  /*Configure GPIO pins : DRV1_CS_Pin DRV2_CS_Pin LED_STATUS_Pin BRAKE_B_RELEASE_Pin */
  GPIO_InitStruct.Pin = DRV1_CS_Pin|DRV2_CS_Pin|LED_STATUS_Pin|BRAKE_B_RELEASE_Pin;
  GPIO_InitStruct.Mode = GPIO_MODE_OUTPUT_PP;
  GPIO_InitStruct.Pull = GPIO_NOPULL;
  GPIO_InitStruct.Speed = GPIO_SPEED_FREQ_LOW;
  HAL_GPIO_Init(GPIOC, &GPIO_InitStruct);

  /*Configure GPIO pin : DRV_FAULT__Pin */
  GPIO_InitStruct.Pin = DRV_FAULT__Pin;
  GPIO_InitStruct.Mode = GPIO_MODE_INPUT;
  GPIO_InitStruct.Pull = GPIO_NOPULL;
  HAL_GPIO_Init(DRV_FAULT__GPIO_Port, &GPIO_InitStruct);

  /*Configure GPIO pins : GATE_M2_ENABLE_Pin OUTPUT_1_Pin OUTPUT_2_Pin */
  GPIO_InitStruct.Pin = GATE_M2_ENABLE_Pin|OUTPUT_1_Pin|OUTPUT_2_Pin;
  GPIO_InitStruct.Mode = GPIO_MODE_OUTPUT_PP;
  GPIO_InitStruct.Pull = GPIO_NOPULL;
  GPIO_InitStruct.Speed = GPIO_SPEED_FREQ_LOW;
  HAL_GPIO_Init(GPIOB, &GPIO_InitStruct);

  /*Configure GPIO pins : DRV_CAL_Pin GATE_M1_ENABLE_Pin */
  GPIO_InitStruct.Pin = DRV_CAL_Pin|GATE_M1_ENABLE_Pin;
  GPIO_InitStruct.Mode = GPIO_MODE_OUTPUT_PP;
  GPIO_InitStruct.Pull = GPIO_NOPULL;
  GPIO_InitStruct.Speed = GPIO_SPEED_FREQ_LOW;
  HAL_GPIO_Init(GPIOE, &GPIO_InitStruct);

  /*Configure GPIO pin : QUAD_Z_M1_Pin */
  GPIO_InitStruct.Pin = QUAD_Z_M1_Pin;
  GPIO_InitStruct.Mode = GPIO_MODE_IT_RISING;
  GPIO_InitStruct.Pull = GPIO_NOPULL;
  HAL_GPIO_Init(QUAD_Z_M1_GPIO_Port, &GPIO_InitStruct);

  /*Configure GPIO pins : M1_SW1_Pin M1_SW2_Pin DIRECTION_A_Pin DIRECTION_B_Pin
                           M2_SW1_Pin M2_SW2_Pin */
  GPIO_InitStruct.Pin = M1_SW1_Pin|M1_SW2_Pin|DIRECTION_A_Pin|DIRECTION_B_Pin
                          |M2_SW1_Pin|M2_SW2_Pin;
  GPIO_InitStruct.Mode = GPIO_MODE_INPUT;
  GPIO_InitStruct.Pull = GPIO_NOPULL;
  HAL_GPIO_Init(GPIOD, &GPIO_InitStruct);

  /*Configure GPIO pin : LED_WARN_Pin */
  GPIO_InitStruct.Pin = LED_WARN_Pin;
  GPIO_InitStruct.Mode = GPIO_MODE_OUTPUT_PP;
  GPIO_InitStruct.Pull = GPIO_NOPULL;
  GPIO_InitStruct.Speed = GPIO_SPEED_FREQ_LOW;
  HAL_GPIO_Init(LED_WARN_GPIO_Port, &GPIO_InitStruct);

  /*Configure GPIO pin : QUAD_Z_M2_Pin */
  GPIO_InitStruct.Pin = QUAD_Z_M2_Pin;
  GPIO_InitStruct.Mode = GPIO_MODE_IT_RISING;
  GPIO_InitStruct.Pull = GPIO_NOPULL;
  HAL_GPIO_Init(QUAD_Z_M2_GPIO_Port, &GPIO_InitStruct);

}

void StartDefaultTask(void *argument)
{
  /* init code for USB_DEVICE */
  MX_USB_DEVICE_Init();
  /* USER CODE BEGIN 5 */
  /* Infinite loop */
  application_main();
  for(;;)
  {
    HAL_GPIO_TogglePin(LED_STATUS_GPIO_Port, LED_STATUS_Pin);
    osDelay(500);
    HAL_GPIO_TogglePin(LED_STATUS_GPIO_Port, LED_STATUS_Pin);
    osDelay(500);
  }
  /* USER CODE END 5 */
}

void HAL_TIM_PeriodElapsedCallback(TIM_HandleTypeDef *htim)
{
  if (htim->Instance == TIM7) {
    HAL_IncTick();
  }
}

void Error_Handler(void)
{
  __disable_irq();
  while (1)
  {
  }
}
